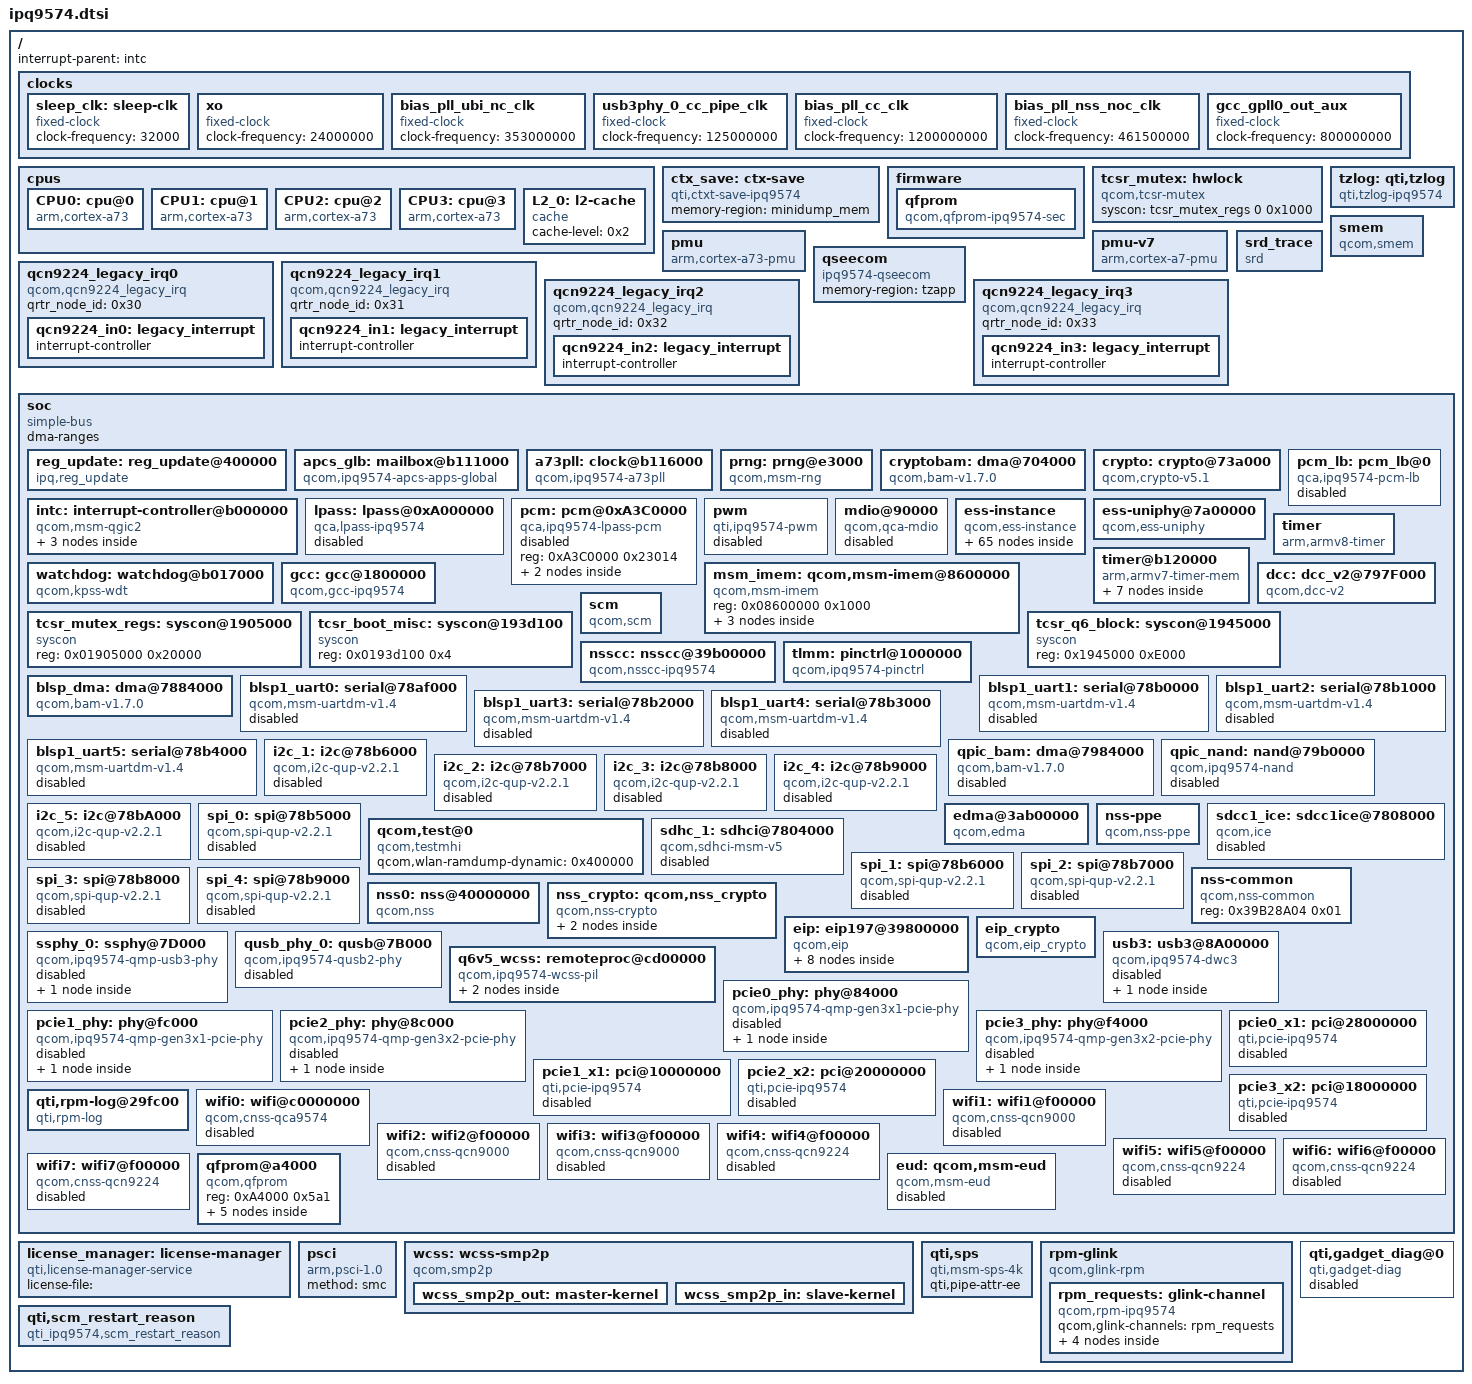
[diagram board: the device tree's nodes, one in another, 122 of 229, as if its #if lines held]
// SPDX-License-Identifier: (GPL-2.0+ OR BSD-3-Clause)
/*
 * IPQ9574 SoC device tree source
 *
 * Copyright (c) 2020-2021 The Linux Foundation. All rights reserved.
 * Copyright (c) 2022-2024, Qualcomm Innovation Center, Inc. All rights reserved.
 */

#include <dt-bindings/interrupt-controller/arm-gic.h>
#include <dt-bindings/clock/qcom,gcc-ipq9574.h>
#include <dt-bindings/reset/qcom,gcc-ipq9574.h>
#include <dt-bindings/clock/qcom,nsscc-ipq9574.h>
#include <dt-bindings/reset/qcom,nsscc-ipq9574.h>
#include <dt-bindings/soc/qcom,dcc_v2.h>
#include <dt-bindings/clock/qcom,apss-ipq.h>
#include <dt-bindings/input/input.h>
#include <dt-bindings/gpio/gpio.h>


/ {
	#address-cells = <2>;
	#size-cells = <2>;
	interrupt-parent = <&intc>;

	clocks {
		sleep_clk: sleep-clk {
			compatible = "fixed-clock";
			clock-frequency = <32000>;
			#clock-cells = <0>;
		};

		xo: xo {
			compatible = "fixed-clock";
			clock-frequency = <24000000>;
			#clock-cells = <0>;
		};

		bias_pll_ubi_nc_clk: bias_pll_ubi_nc_clk {
			compatible = "fixed-clock";
			clock-frequency = <353000000>;
			#clock-cells = <0>;
		};

		usb3phy_0_cc_pipe_clk: usb3phy_0_cc_pipe_clk {
			compatible = "fixed-clock";
			clock-frequency = <125000000>;
			#clock-cells = <0>;
		};

		bias_pll_cc_clk: bias_pll_cc_clk {
			compatible = "fixed-clock";
			clock-frequency = <1200000000>;
			#clock-cells = <0>;
		};

		bias_pll_nss_noc_clk: bias_pll_nss_noc_clk {
			compatible = "fixed-clock";
			clock-frequency = <461500000>;
			#clock-cells = <0>;
		};

		gcc_gpll0_out_aux: gcc_gpll0_out_aux {
			compatible = "fixed-clock";
			clock-frequency = <800000000>;
			#clock-cells = <0>;
		};
	};

	cpus: cpus {
		#address-cells = <1>;
		#size-cells = <0>;

		CPU0: cpu@0 {
			device_type = "cpu";
			compatible = "arm,cortex-a73";
			reg = <0x0>;
			enable-method = "psci";
			next-level-cache = <&L2_0>;
			clocks = <&apcs_glb APCS_ALIAS0_CORE_CLK>;
			clock-names = "cpu";
		};

		CPU1: cpu@1 {
			device_type = "cpu";
			compatible = "arm,cortex-a73";
			enable-method = "psci";
			reg = <0x1>;
			next-level-cache = <&L2_0>;
			clocks = <&apcs_glb APCS_ALIAS0_CORE_CLK>;
			clock-names = "cpu";
		};

		CPU2: cpu@2 {
			device_type = "cpu";
			compatible = "arm,cortex-a73";
			enable-method = "psci";
			reg = <0x2>;
			next-level-cache = <&L2_0>;
			clocks = <&apcs_glb APCS_ALIAS0_CORE_CLK>;
			clock-names = "cpu";
		};

		CPU3: cpu@3 {
			device_type = "cpu";
			compatible = "arm,cortex-a73";
			enable-method = "psci";
			reg = <0x3>;
			next-level-cache = <&L2_0>;
			clocks = <&apcs_glb APCS_ALIAS0_CORE_CLK>;
			clock-names = "cpu";
		};

		L2_0: l2-cache {
			compatible = "cache";
			cache-level = <0x2>;
		};
	};

	ctx_save: ctx-save {
		compatible = "qti,ctxt-save-ipq9574";
		memory-region = <&minidump_mem>;
	};

	firmware {
		qfprom {
			compatible = "qcom,qfprom-ipq9574-sec";
			img-addr = <0x4A100000>;
			img-size = <0x00500000>;
			scm-cmd-id = <0x1F>;
		};
	};

	tcsr_mutex: hwlock {
		compatible = "qcom,tcsr-mutex";
		syscon = <&tcsr_mutex_regs 0 0x1000>;
		#hwlock-cells = <1>;
	};

	pmu {
		compatible = "arm,cortex-a73-pmu";
		interrupts = <GIC_PPI 7 (GIC_CPU_MASK_SIMPLE(4) | IRQ_TYPE_LEVEL_HIGH)>;
	};

	pmu-v7 {
		compatible = "arm,cortex-a7-pmu";
		interrupts = <GIC_PPI 7 (GIC_CPU_MASK_SIMPLE(4) | IRQ_TYPE_LEVEL_HIGH)>;
	};

	tzlog: qti,tzlog {
		compatible = "qti,tzlog-ipq9574";
		interrupts = <GIC_SPI 244 IRQ_TYPE_EDGE_RISING>;
		qti,tz-diag-buf-size = <0x3000>;
		qti,tz-ring-off = <7>;
		qti,tz-log-pos-info-off = <810>;
		qti,hvc-enabled;
		qti,get-smmu-state;
	};

	smem {
		compatible = "qcom,smem";
		memory-region = <&smem_region>;
		hwlocks = <&tcsr_mutex 3>;
	};

	qseecom: qseecom {
		compatible = "ipq9574-qseecom";
		memory-region = <&tzapp>;
		status = "ok";
	};

	qcn9224_legacy_irq0: qcn9224_legacy_irq0 {
		compatible = "qcom,qcn9224_legacy_irq";
		status = "ok";
		qrtr_node_id = <0x30>;
		qcn9224_in0: legacy_interrupt {
			interrupt-controller;
			#interrupt-cells = <2>;
		};
	};

	qcn9224_legacy_irq1: qcn9224_legacy_irq1 {
		compatible = "qcom,qcn9224_legacy_irq";
		status = "ok";
		qrtr_node_id = <0x31>;
		qcn9224_in1: legacy_interrupt {
			interrupt-controller;
			#interrupt-cells = <2>;
		};
	};

	qcn9224_legacy_irq2: qcn9224_legacy_irq2 {
		compatible = "qcom,qcn9224_legacy_irq";
		status = "ok";
		qrtr_node_id = <0x32>;
		qcn9224_in2: legacy_interrupt {
			interrupt-controller;
			#interrupt-cells = <2>;
		};
	};

	qcn9224_legacy_irq3: qcn9224_legacy_irq3 {
		compatible = "qcom,qcn9224_legacy_irq";
		status = "ok";
		qrtr_node_id = <0x33>;
		qcn9224_in3: legacy_interrupt {
			interrupt-controller;
			#interrupt-cells = <2>;
		};
	};

	srd_trace: srd_trace {
		compatible = "srd";
	};

	soc: soc {
		#address-cells = <1>;
		#size-cells = <1>;
		ranges = <0 0 0 0xffffffff>;
		dma-ranges;
		compatible = "simple-bus";

		reg_update: reg_update@400000 {
			compatible = "ipq,reg_update";
			reg = <0x00400000 0x6148>,<0x39D00020 0x10>;
			reg-names = "memnoc","ubicore";
			clocks = <&nsscc NSS_CC_NSS_CSR_CLK>,
				 <&nsscc NSS_CC_NSSNOC_NSS_CSR_CLK>;
			clock-names = "nss-csr-clk", "nss-nssnoc-csr-clk";
			assigned-clocks = <&nsscc NSS_CC_NSS_CSR_CLK>,
					  <&nsscc NSS_CC_NSSNOC_NSS_CSR_CLK>;
			assigned-clock-rates = <100000000>,<100000000>;
			status = "ok";
		};

		apcs_glb: mailbox@b111000 {
			compatible = "qcom,ipq9574-apcs-apps-global";
			reg = <0x0b111000 0x1000>;
			#clock-cells = <1>;
			clocks = <&a73pll>, <&xo>;
			clock-names = "pll", "xo";
			apcs-max-register = <0xFFC>;

			#mbox-cells = <1>;
		};

		a73pll: clock@b116000 {
			compatible = "qcom,ipq9574-a73pll";
			reg = <0x0b116000 0x40>;
			#clock-cells = <0>;
			clocks = <&xo>;
			clock-names = "xo";
		};

		prng: prng@e3000 {
			compatible = "qcom,msm-rng";
			reg = <0xe3000 0x1000>;
			clocks = <&gcc GCC_PRNG_AHB_CLK>;
			clock-names = "km_clk_src";
			qcom,no-qrng-config;
		};

		cryptobam: dma@704000 {
			compatible = "qcom,bam-v1.7.0";
			reg = <0x00704000 0x20000>;
			interrupts = <GIC_SPI 207 IRQ_TYPE_LEVEL_HIGH>;
			#dma-cells = <1>;
			qcom,ee = <1>;
			qcom,controlled-remotely = <1>;
		};

		crypto: crypto@73a000 {
			compatible = "qcom,crypto-v5.1";
			reg = <0x0073a000 0x6000>;
			dmas = <&cryptobam 2>, <&cryptobam 3>;
			dma-names = "rx", "tx";
			qce,no-clock-init;
			qce,cmd_desc_support;
		};

		intc: interrupt-controller@b000000 {
			compatible = "qcom,msm-qgic2";
			interrupt-controller;
			#interrupt-cells = <0x3>;
			reg = <0x0b000000 0x1000>,  /*GICD*/
				<0x0b002000 0x1000>,  /*GICC*/
				<0x0b001000 0x1000>,  /*GICH*/
				<0x0b004000 0x1000>;  /*GICV*/
			interrupts = <GIC_PPI 9 IRQ_TYPE_LEVEL_HIGH>;
			ranges = <0 0x0b00c000 0x3000>;

			v2m0: v2m@0 {
				compatible = "arm,gic-v2m-frame";
				msi-controller;
				reg = <0x0 0xffd>;
			};

			v2m1: v2m@1 {
				compatible = "arm,gic-v2m-frame";
				msi-controller;
				reg = <0x1000 0xffd>;
			};

			v2m2: v2m@2 {
				compatible = "arm,gic-v2m-frame";
				msi-controller;
				reg = <0x2000 0xffd>;
			};
		};

		lpass: lpass@0xA000000{
			compatible = "qca,lpass-ipq9574";
			reg =  <0xA000000 0x3BFFFF>;
			clocks = <&gcc GCC_LPASS_SWAY_CLK>,
			<&gcc GCC_LPASS_CORE_AXIM_CLK>,
			<&gcc GCC_SNOC_LPASS_CFG_CLK>,
			<&gcc GCC_PCNOC_LPASS_CLK>;
			clock-names = "sway", "axim", "snoc_cfg", "pcnoc";
			resets = <&gcc GCC_LPASS_BCR>;
			reset-names = "lpass";
			status = "disabled";
		};

		pcm: pcm@0xA3C0000{
			compatible = "qca,ipq9574-lpass-pcm";
			reg =  <0xA3C0000 0x23014>;
			status = "disabled";

			pcm0: pcm0@0 {
				interrupts = <0 419 IRQ_TYPE_LEVEL_HIGH>;
				interrupt-names = "out0";
				capture_memory = "lpm";
				playback_memory = "lpm";
				voice_loopback = <0>;
				slave = <0>;
				status = "disabled";
			      };

			pcm1: pcm1@1 {
				interrupts = <0 117 IRQ_TYPE_LEVEL_HIGH>;
				interrupt-names = "out1";
				capture_memory = "lpm";
				playback_memory = "lpm";
				voice_loopback = <0>;
				slave = <0>;
				status = "disabled";
			};

		};

		pcm_lb: pcm_lb@0 {
			compatible = "qca,ipq9574-pcm-lb";
			status = "disabled";
		};

		pwm {
			compatible = "qti,ipq9574-pwm";
			reg = <0x1941010 0x20>;
			clocks = <&gcc GCC_ADSS_PWM_CLK>;
			clock-names = "core";
			src-freq = <100000000>;
			pwm-base-index = <0>;
			used-pwm-indices = <1>, <1>, <1>, <1>;
			status = "disabled";
		};

		mdio@90000 {
			#address-cells = <1>;
			#size-cells = <1>;
			compatible = "qcom,qca-mdio", "qcom,ipq40xx-mdio";
			reg = <0x90000 0x64>, <0x9B000 0x800>;
			clocks = <&gcc GCC_MDIO_AHB_CLK>;
			clock-names = "gcc_mdio_ahb_clk";
			status = "disabled";
		};

		ess-instance {
			compatible = "qcom,ess-instance";
			ess-switch@3a000000 {
				compatible = "qcom,ess-switch-ipq95xx";
				switch_access_mode = "local bus";
				reg = <0x3a000000 0x1000000>;
				switch_cpu_bmp = <0x1>;  /* cpu port bitmap */
				switch_inner_bmp = <0x80>; /*inner port bitmap*/
				clocks = <&gcc GCC_CMN_12GPLL_AHB_CLK>,
					<&gcc GCC_CMN_12GPLL_SYS_CLK>,
					<&gcc GCC_UNIPHY0_AHB_CLK>,
					<&gcc GCC_UNIPHY0_SYS_CLK>,
					<&gcc GCC_UNIPHY1_AHB_CLK>,
					<&gcc GCC_UNIPHY1_SYS_CLK>,
					<&gcc GCC_UNIPHY2_AHB_CLK>,
					<&gcc GCC_UNIPHY2_SYS_CLK>,
					<&gcc GCC_NSSNOC_NSSCC_CLK>,
					<&gcc GCC_NSSCC_CLK>,
					<&gcc GCC_NSSNOC_SNOC_1_CLK>,
					<&gcc GCC_NSSNOC_SNOC_CLK>,
					<&nsscc NSS_CC_PORT1_MAC_CLK>,
					<&nsscc NSS_CC_PORT2_MAC_CLK>,
					<&nsscc NSS_CC_PORT3_MAC_CLK>,
					<&nsscc NSS_CC_PORT4_MAC_CLK>,
					<&nsscc NSS_CC_PORT5_MAC_CLK>,
					<&nsscc NSS_CC_PORT6_MAC_CLK>,
					<&nsscc NSS_CC_PPE_SWITCH_CLK>,
					<&nsscc NSS_CC_PPE_SWITCH_CFG_CLK>,
					<&nsscc NSS_CC_NSSNOC_PPE_CLK>,
					<&nsscc NSS_CC_NSSNOC_PPE_CFG_CLK>,
					<&nsscc NSS_CC_PPE_EDMA_CLK>,
					<&nsscc NSS_CC_PPE_EDMA_CFG_CLK>,
					<&nsscc NSS_CC_PPE_SWITCH_IPE_CLK>,
					<&nsscc NSS_CC_PPE_SWITCH_BTQ_CLK>,
					<&nsscc NSS_CC_PORT1_RX_CLK>,
					<&nsscc NSS_CC_PORT1_TX_CLK>,
					<&nsscc NSS_CC_PORT2_RX_CLK>,
					<&nsscc NSS_CC_PORT2_TX_CLK>,
					<&nsscc NSS_CC_PORT3_RX_CLK>,
					<&nsscc NSS_CC_PORT3_TX_CLK>,
					<&nsscc NSS_CC_PORT4_RX_CLK>,
					<&nsscc NSS_CC_PORT4_TX_CLK>,
					<&nsscc NSS_CC_PORT5_RX_CLK>,
					<&nsscc NSS_CC_PORT5_TX_CLK>,
					<&nsscc NSS_CC_PORT6_RX_CLK>,
					<&nsscc NSS_CC_PORT6_TX_CLK>,
					<&nsscc NSS_CC_UNIPHY_PORT1_RX_CLK>,
					<&nsscc NSS_CC_UNIPHY_PORT1_TX_CLK>,
					<&nsscc NSS_CC_UNIPHY_PORT2_RX_CLK>,
					<&nsscc NSS_CC_UNIPHY_PORT2_TX_CLK>,
					<&nsscc NSS_CC_UNIPHY_PORT3_RX_CLK>,
					<&nsscc NSS_CC_UNIPHY_PORT3_TX_CLK>,
					<&nsscc NSS_CC_UNIPHY_PORT4_RX_CLK>,
					<&nsscc NSS_CC_UNIPHY_PORT4_TX_CLK>,
					<&nsscc NSS_CC_UNIPHY_PORT5_RX_CLK>,
					<&nsscc NSS_CC_UNIPHY_PORT5_TX_CLK>,
					<&nsscc NSS_CC_UNIPHY_PORT6_RX_CLK>,
					<&nsscc NSS_CC_UNIPHY_PORT6_TX_CLK>,
					<&nsscc NSS_CC_PORT5_RX_CLK_SRC>,
					<&nsscc NSS_CC_PORT5_TX_CLK_SRC>;
				clock-names = "cmn_ahb_clk",
					"cmn_sys_clk",
					"uniphy0_ahb_clk",
					"uniphy0_sys_clk",
					"uniphy1_ahb_clk",
					"uniphy1_sys_clk",
					"uniphy2_ahb_clk",
					"uniphy2_sys_clk",
					"gcc_nssnoc_nsscc_clk",
					"gcc_nsscc_clk",
					"gcc_nssnoc_snoc_1_clk",
					"gcc_nssnoc_snoc_clk",
					"port1_mac_clk",
					"port2_mac_clk",
					"port3_mac_clk",
					"port4_mac_clk",
					"port5_mac_clk",
					"port6_mac_clk",
					"nss_ppe_clk",
					"nss_ppe_cfg_clk",
					"nssnoc_ppe_clk",
					"nssnoc_ppe_cfg_clk",
					"nss_edma_clk",
					"nss_edma_cfg_clk",
					"nss_ppe_ipe_clk",
					"nss_ppe_btq_clk",
					"nss_port1_rx_clk", "nss_port1_tx_clk",
					"nss_port2_rx_clk", "nss_port2_tx_clk",
					"nss_port3_rx_clk", "nss_port3_tx_clk",
					"nss_port4_rx_clk", "nss_port4_tx_clk",
					"nss_port5_rx_clk", "nss_port5_tx_clk",
					"nss_port6_rx_clk", "nss_port6_tx_clk",
					"uniphy0_port1_rx_clk",
					"uniphy0_port1_tx_clk",
					"uniphy0_port2_rx_clk",
					"uniphy0_port2_tx_clk",
					"uniphy0_port3_rx_clk",
					"uniphy0_port3_tx_clk",
					"uniphy0_port4_rx_clk",
					"uniphy0_port4_tx_clk",
					"uniphy0_port5_rx_clk",
					"uniphy0_port5_tx_clk",
					"uniphy2_port6_rx_clk",
					"uniphy2_port6_tx_clk",
					"nss_port5_rx_clk_src",
					"nss_port5_tx_clk_src";
				resets = <&nsscc PPE_FULL_RESET>,
					<&nsscc UNIPHY0_SOFT_RESET>,
					<&gcc GCC_UNIPHY0_XPCS_RESET>,
					<&nsscc UNIPHY_PORT5_ARES>,
					<&gcc GCC_UNIPHY1_XPCS_RESET>,
					<&nsscc UNIPHY_PORT6_ARES>,
					<&gcc GCC_UNIPHY2_XPCS_RESET>,
					<&nsscc UNIPHY_PORT1_ARES>,
					<&nsscc UNIPHY_PORT2_ARES>,
					<&nsscc UNIPHY_PORT3_ARES>,
					<&nsscc UNIPHY_PORT4_ARES>,
					<&gcc GCC_UNIPHY0_SYS_RESET>,
					<&gcc GCC_UNIPHY1_SYS_RESET>,
					<&gcc GCC_UNIPHY2_SYS_RESET>,
					<&nsscc NSSPORT1_RESET>,
					<&nsscc NSSPORT2_RESET>,
					<&nsscc NSSPORT3_RESET>,
					<&nsscc NSSPORT4_RESET>,
					<&nsscc NSSPORT5_RESET>,
					<&nsscc NSSPORT6_RESET>,
					<&nsscc PORT1_MAC_ARES>,
					<&nsscc PORT2_MAC_ARES>,
					<&nsscc PORT3_MAC_ARES>,
					<&nsscc PORT4_MAC_ARES>,
					<&nsscc PORT5_MAC_ARES>,
					<&nsscc PORT6_MAC_ARES>;
				reset-names = "ppe_rst",
					"uniphy0_soft_rst",
					"uniphy0_xpcs_rst",
					"uniphy1_soft_rst",
					"uniphy1_xpcs_rst",
					"uniphy2_soft_rst",
					"uniphy2_xpcs_rst",
					"uniphy0_port1_dis",
					"uniphy0_port2_dis",
					"uniphy0_port3_dis",
					"uniphy0_port4_dis",
					"uniphy0_sys_rst",
					"uniphy1_sys_rst",
					"uniphy2_sys_rst",
					"nss_port1_rst",
					"nss_port2_rst",
					"nss_port3_rst",
					"nss_port4_rst",
					"nss_port5_rst",
					"nss_port6_rst",
					"nss_port1_mac_rst",
					"nss_port2_mac_rst",
					"nss_port3_mac_rst",
					"nss_port4_mac_rst",
					"nss_port5_mac_rst",
					"nss_port6_mac_rst";
				port_scheduler_resource {
					port@0 {
						port_id = <0>;
						ucast_queue = <0 63>;
						mcast_queue = <256 263>;
						l0sp = <0 0>;
						l0cdrr = <0 7>;
						l0edrr = <0 7>;
						l1cdrr = <0 0>;
						l1edrr = <0 0>;
					};
					port@1 {
						port_id = <1>;
						ucast_queue = <204 211>;
						mcast_queue = <272 275>;
						l0sp = <51 52>;
						l0cdrr = <108 115>;
						l0edrr = <108 115>;
						l1cdrr = <23 24>;
						l1edrr = <23 24>;
					};
					port@2 {
						port_id = <2>;
						ucast_queue = <212 219>;
						mcast_queue = <276 279>;
						l0sp = <53 54>;
						l0cdrr = <116 123>;
						l0edrr = <116 123>;
						l1cdrr = <25 26>;
						l1edrr = <25 26>;
					};
					port@3 {
						port_id = <3>;
						ucast_queue = <220 227>;
						mcast_queue = <280 283>;
						l0sp = <55 56>;
						l0cdrr = <124 131>;
						l0edrr = <124 131>;
						l1cdrr = <27 28>;
						l1edrr = <27 28>;
					};
					port@4 {
						port_id = <4>;
						ucast_queue = <228 235>;
						mcast_queue = <284 287>;
						l0sp = <57 58>;
						l0cdrr = <132 139>;
						l0edrr = <132 139>;
						l1cdrr = <29 30>;
						l1edrr = <29 30>;
					};
					port@5 {
						port_id = <5>;
						ucast_queue = <236 243>;
						mcast_queue = <288 291>;
						l0sp = <59 60>;
						l0cdrr = <140 147>;
						l0edrr = <140 147>;
						l1cdrr = <31 32>;
						l1edrr = <31 32>;
					};
					port@6 {
						port_id = <6>;
						ucast_queue = <244 251>;
						mcast_queue = <292 295>;
						l0sp = <61 62>;
						l0cdrr = <148 155>;
						l0edrr = <148 155>;
						l1cdrr = <33 34>;
						l1edrr = <33 34>;
					};
					port@7 {
						port_id = <7>;
						ucast_queue = <252 255>;
						mcast_queue = <296 299>;
						l0sp = <63 63>;
						l0cdrr = <156 159>;
						l0edrr = <156 159>;
						l1cdrr = <35 35>;
						l1edrr = <35 35>;
					};
					reserved {
						ucast_queue = <64 203>;
						mcast_queue = <264 271>;
						l0sp = <1 50>;
						l0cdrr = <8 107>;
						l0edrr = <8 107>;
						l1cdrr = <1 22>;
						l1edrr = <1 22>;
					};
				};
				port_scheduler_config {
					port@0 {
						port_id = <0>;
						l1scheduler {
							group@0 {
								/* L0 SP */
								sp = <0>;
								/* cpri cdrr epri edrr */
								cfg = <0 0 0 0>;
							};
						};
						l0scheduler {
							group@0 {
								/* unicast queue */
								ucast_queue = <0>;
								ucast_loop_pri = <8>;
								/* multicast queue */
								mcast_queue = <256>;
								/* sp cpri cdrr epri edrr */
								cfg = <0 0 0 0 0>;
							};
							group@1 {
								ucast_queue = <8>;
								ucast_loop_pri = <8>;
								mcast_queue = <257>;
								cfg = <0 0 0 0 0>;
							};
							group@2 {
								ucast_queue = <16>;
								ucast_loop_pri = <8>;
								mcast_queue = <258>;
								cfg = <0 0 0 0 0>;
							};
							group@3 {
								ucast_queue = <24>;
								ucast_loop_pri = <8>;
								mcast_queue = <259>;
								cfg = <0 0 0 0 0>;
							};
							group@4 {
								ucast_queue = <32>;
								ucast_loop_pri = <8>;
								mcast_queue = <260>;
								cfg = <0 0 0 0 0>;
							};
							group@5 {
								ucast_queue = <40>;
								ucast_loop_pri = <8>;
								mcast_queue = <261>;
								cfg = <0 0 0 0 0>;
							};
							group@6 {
								ucast_queue = <48>;
								ucast_loop_pri = <8>;
								mcast_queue = <262>;
								cfg = <0 0 0 0 0>;
							};
							group@7 {
								ucast_queue = <56>;
								ucast_loop_pri = <8>;
								mcast_queue = <263>;
								cfg = <0 0 0 0 0>;
							};
						};
					};
					port@1 {
						port_id = <1>;
						l1scheduler {
							group@0 {
								sp = <51>;
								cfg = <0 23 0 23>;
							};
							group@1 {
								sp = <52>;
								cfg = <1 24 1 24>;
							};
						};
						l0scheduler {
							group@0 {
								ucast_queue = <204>;
								ucast_loop_pri = <8>;
								/* max priority per SP */
								ucast_max_pri = <4>;
								mcast_queue = <272>;
								mcast_loop_pri = <4>;
								cfg = <51 0 108 0 108>;
							};
						};
					};
					port@2 {
						port_id = <2>;
						l1scheduler {
							group@0 {
								sp = <53>;
								cfg = <0 25 0 25>;
							};
							group@1 {
								sp = <54>;
								cfg = <1 26 1 26>;
							};
						};
						l0scheduler {
							group@0 {
								ucast_queue = <212>;
								ucast_loop_pri = <8>;
								ucast_max_pri = <4>;
								mcast_queue = <276>;
								mcast_loop_pri = <4>;
								cfg = <53 0 116 0 116>;
							};
						};
					};
					port@3 {
						port_id = <3>;
						l1scheduler {
							group@0 {
								sp = <55>;
								cfg = <0 27 0 27>;
							};
							group@1 {
								sp = <56>;
								cfg = <1 28 1 28>;
							};
						};
						l0scheduler {
							group@0 {
								ucast_queue = <220>;
								ucast_loop_pri = <8>;
								ucast_max_pri = <4>;
								mcast_queue = <280>;
								mcast_loop_pri = <4>;
								cfg = <55 0 124 0 124>;
							};
						};
					};
					port@4 {
						port_id = <4>;
						l1scheduler {
							group@0 {
								sp = <57>;
								cfg = <0 29 0 29>;
							};
							group@1 {
								sp = <58>;
								cfg = <1 30 1 30>;
							};
						};
						l0scheduler {
							group@0 {
								ucast_queue = <228>;
								ucast_loop_pri = <8>;
								ucast_max_pri = <4>;
								mcast_queue = <284>;
								mcast_loop_pri = <4>;
								cfg = <57 0 132 0 132>;
							};
						};
					};
					port@5 {
						port_id = <5>;
						l1scheduler {
							group@0 {
								sp = <59>;
								cfg = <0 31 0 31>;
							};
							group@1 {
								sp = <60>;
								cfg = <1 32 1 32>;
							};
						};
						l0scheduler {
							group@0 {
								ucast_queue = <236>;
								ucast_loop_pri = <8>;
								ucast_max_pri = <4>;
								mcast_queue = <288>;
								mcast_loop_pri = <4>;
								cfg = <59 0 140 0 140>;
							};
						};
					};
					port@6 {
						port_id = <6>;
						l1scheduler {
							group@0 {
								sp = <61>;
								cfg = <0 33 0 33>;
							};
							group@1 {
								sp = <62>;
								cfg = <1 34 1 34>;
							};
						};
						l0scheduler {
							group@0 {
								ucast_queue = <244>;
								ucast_loop_pri = <8>;
								ucast_max_pri = <4>;
								mcast_queue = <292>;
								mcast_loop_pri = <4>;
								cfg = <61 0 148 0 148>;
							};
						};
					};
					port@7 {
						port_id = <7>;
						l1scheduler {
							group@0 {
								sp = <63>;
								cfg = <0 35 0 35>;
							};
						};
						l0scheduler {
							group@0 {
								ucast_queue = <252>;
								ucast_loop_pri = <4>;
								ucast_max_pri = <4>;
								mcast_queue = <296>;
								mcast_loop_pri = <4>;
								cfg = <63 0 156 0 156>;
							};
						};
					};
				};
			};
		};

		ess-uniphy@7a00000 {
			compatible = "qcom,ess-uniphy";
			reg = <0x7a00000 0x30000>;
			uniphy_access_mode = "local bus";
		};

		timer {
			compatible = "arm,armv8-timer";
			interrupts = <GIC_PPI 2 (GIC_CPU_MASK_SIMPLE(4) | IRQ_TYPE_LEVEL_LOW)>,
				<GIC_PPI 3 (GIC_CPU_MASK_SIMPLE(4) | IRQ_TYPE_LEVEL_LOW)>,
				<GIC_PPI 4 (GIC_CPU_MASK_SIMPLE(4) | IRQ_TYPE_LEVEL_LOW)>,
				<GIC_PPI 1 (GIC_CPU_MASK_SIMPLE(4) | IRQ_TYPE_LEVEL_LOW)>;
			clock-frequency = <24000000>;
		};

		watchdog: watchdog@b017000 {
			compatible = "qcom,kpss-wdt";
			reg = <0xb017000 0x1000>;
			interrupts = <GIC_SPI 3 IRQ_TYPE_EDGE_RISING>;
			clocks = <&sleep_clk>;
		};

		timer@b120000 {
			#address-cells = <1>;
			#size-cells = <1>;
			ranges;
			compatible = "arm,armv7-timer-mem";
			reg = <0xb120000 0x1000>;
			clock-frequency = <24000000>;

			frame@b120000 {
				frame-number = <0>;
				interrupts = <GIC_SPI 8 IRQ_TYPE_LEVEL_HIGH>,
					     <GIC_SPI 7 IRQ_TYPE_LEVEL_HIGH>;
				reg = <0xb121000 0x1000>,
				      <0xb122000 0x1000>;
			};

			frame@b123000 {
				frame-number = <1>;
				interrupts = <GIC_SPI 9 IRQ_TYPE_LEVEL_HIGH>;
				reg = <0xb123000 0x1000>;
				status = "disabled";
			};

			frame@b124000 {
				frame-number = <2>;
				interrupts = <GIC_SPI 10 IRQ_TYPE_LEVEL_HIGH>;
				reg = <0xb124000 0x1000>;
				status = "disabled";
			};

			frame@b125000 {
				frame-number = <3>;
				interrupts = <GIC_SPI 11 IRQ_TYPE_LEVEL_HIGH>;
				reg = <0xb125000 0x1000>;
				status = "disabled";
			};

			frame@b126000 {
				frame-number = <4>;
				interrupts = <GIC_SPI 12 IRQ_TYPE_LEVEL_HIGH>;
				reg = <0xb126000 0x1000>;
				status = "disabled";
			};

			frame@b127000 {
				frame-number = <5>;
				interrupts = <GIC_SPI 13 IRQ_TYPE_LEVEL_HIGH>;
				reg = <0xb127000 0x1000>;
				status = "disabled";
			};

			frame@b128000 {
				frame-number = <6>;
				interrupts = <GIC_SPI 14 IRQ_TYPE_LEVEL_HIGH>;
				reg = <0xb128000 0x1000>;
				status = "disabled";
			};
		};

		gcc: gcc@1800000 {
			compatible = "qcom,gcc-ipq9574";
			reg = <0x1800000 0x80000>;
			clocks = <&xo>, <&sleep_clk>;
			clock-names = "xo", "sleep_clk";
			#clock-cells = <0x1>;
			#reset-cells = <0x1>;
		};

		msm_imem: qcom,msm-imem@8600000 {
			compatible = "qcom,msm-imem";
			reg = <0x08600000 0x1000>;
			ranges = <0x0 0x08600000 0x1000>;
			#address-cells = <1>;
			#size-cells = <1>;

			mem_dump_table@10 {
				compatible = "qcom,msm-imem-mem_dump_table";
				reg = <0x10 8>;
			};

			tz-log-buf-addr@720 {
				compatible = "qcom,msm-imem-tz-log-buf-addr";
				reg = <0x720 4>;
			};

			restart-reason-buf-addr@7a4 {
				compatible = "qcom,msm-imem-restart-reason-buf-addr";
				reg = <0x7a4 4>;
			};
		};

		dcc: dcc_v2@797F000 {
			compatible = "qcom,dcc-v2";
			status = "ok";
			reg = <0x797F000 0x1000>,
				<0x7906000 0x1000>;
			reg-names = "dcc-base", "dcc-ram-base";

			dcc-ram-offset = <0x6000>;
		};

		tcsr_mutex_regs: syscon@1905000 {
			compatible = "syscon";
			reg = <0x01905000 0x20000>;
		};

		tcsr_boot_misc: syscon@193d100 {
			compatible = "syscon";
			reg = <0x0193d100 0x4>;
		};

		tcsr_q6_block: syscon@1945000 {
			compatible = "syscon";
			reg = <0x1945000 0xE000>;
		};

		scm {
			compatible = "qcom,scm";
			hvc-log-cmd-id = <0xA>;
			smmu-state-cmd-id = <0x20>;
			qcom,dload-mode = <&tcsr_boot_misc 0>;
		};

		nsscc: nsscc@39b00000 {
			compatible = "qcom,nsscc-ipq9574";
			reg = <0x39b00000 0x80000>;
			clocks = <&bias_pll_cc_clk>,
				<&bias_pll_nss_noc_clk>,
				<&bias_pll_ubi_nc_clk>,
				<&gcc_gpll0_out_aux>,
				<&xo>;
			clock-names = "bias_pll_cc_clk",
				"bias_pll_nss_noc_clk",
				"bias_pll_ubi_nc_clk",
				"gcc_gpll0_out_aux",
				"xo";
			#clock-cells = <0x1>;
			#reset-cells = <0x1>;
		};

		tlmm: pinctrl@1000000 {
			compatible = "qcom,ipq9574-pinctrl";
			reg = <0x01000000 0x300000>;
			interrupts = <GIC_SPI 208 IRQ_TYPE_LEVEL_HIGH>;
			gpio-controller;
			#gpio-cells = <2>;
			gpio-ranges = <&tlmm 0 0 65>;
			gpio-reserved-ranges = <59 1>;
			interrupt-controller;
			#interrupt-cells = <2>;
		};

		blsp_dma: dma@7884000 {
			compatible = "qcom,bam-v1.7.0";
			reg = <0x07884000 0x2b000>;
			interrupts = <GIC_SPI 238 IRQ_TYPE_LEVEL_HIGH>;
			clocks = <&gcc GCC_BLSP1_AHB_CLK>;
			clock-names = "bam_clk";
			#dma-cells = <1>;
			qcom,ee = <0>;
		};

		blsp1_uart0: serial@78af000 {
			compatible = "qcom,msm-uartdm-v1.4", "qcom,msm-uartdm";
			reg = <0x078af000 0x200>;
			interrupts = <GIC_SPI 107 IRQ_TYPE_LEVEL_HIGH>;
			clocks = <&gcc GCC_BLSP1_UART1_APPS_CLK>,
				 <&gcc GCC_BLSP1_AHB_CLK>;
			clock-names = "core", "iface";
			status = "disabled";
		};

		blsp1_uart1: serial@78b0000 {
			compatible = "qcom,msm-uartdm-v1.4", "qcom,msm-uartdm";
			reg = <0x078b0000 0x200>;
			interrupts = <GIC_SPI 108 IRQ_TYPE_LEVEL_HIGH>;
			clocks = <&gcc GCC_BLSP1_UART2_APPS_CLK>,
				 <&gcc GCC_BLSP1_AHB_CLK>;
			clock-names = "core", "iface";
			status = "disabled";
		};

		blsp1_uart2: serial@78b1000 {
			compatible = "qcom,msm-uartdm-v1.4", "qcom,msm-uartdm";
			reg = <0x078b1000 0x200>;
			interrupts = <GIC_SPI 306 IRQ_TYPE_LEVEL_HIGH>;
			clocks = <&gcc GCC_BLSP1_UART3_APPS_CLK>,
				 <&gcc GCC_BLSP1_AHB_CLK>;
			clock-names = "core", "iface";
			status = "disabled";
			tx-watermark = <0>;
		};

		blsp1_uart3: serial@78b2000 {
			compatible = "qcom,msm-uartdm-v1.4", "qcom,msm-uartdm";
			reg = <0x078b2000 0x200>;
			interrupts = <GIC_SPI 307 IRQ_TYPE_LEVEL_HIGH>;
			clocks = <&gcc GCC_BLSP1_UART4_APPS_CLK>,
				 <&gcc GCC_BLSP1_AHB_CLK>;
			clock-names = "core", "iface";
			status = "disabled";
		};

		blsp1_uart4: serial@78b3000 {
			compatible = "qcom,msm-uartdm-v1.4", "qcom,msm-uartdm";
			reg = <0x078b3000 0x200>;
			interrupts = <GIC_SPI 308 IRQ_TYPE_LEVEL_HIGH>;
			clocks = <&gcc GCC_BLSP1_UART5_APPS_CLK>,
				 <&gcc GCC_BLSP1_AHB_CLK>;
			clock-names = "core", "iface";
			dmas = <&blsp_dma 8>, <&blsp_dma 9>;
			dma-names = "tx", "rx";
			status = "disabled";
		};

		blsp1_uart5: serial@78b4000 {
			compatible = "qcom,msm-uartdm-v1.4", "qcom,msm-uartdm";
			reg = <0x078b4000 0x200>;
			interrupts = <GIC_SPI 309 IRQ_TYPE_LEVEL_HIGH>;
			clocks = <&gcc GCC_BLSP1_UART6_APPS_CLK>,
				 <&gcc GCC_BLSP1_AHB_CLK>;
			clock-names = "core", "iface";
			status = "disabled";
		};

		qpic_bam: dma@7984000 {
			compatible = "qcom,bam-v1.7.0";
			reg = <0x7984000 0x1c000>;
			interrupts = <GIC_SPI 146 IRQ_TYPE_LEVEL_HIGH>;
			clocks = <&gcc GCC_QPIC_AHB_CLK>;
			clock-names = "bam_clk";
			#dma-cells = <1>;
			qcom,ee = <0>;
			status = "disabled";
		};

		qpic_nand: nand@79b0000 {
			compatible = "qcom,ipq9574-nand";
			reg = <0x79b0000 0x10000>;
			#address-cells = <1>;
			#size-cells = <0>;
			clocks = <&gcc GCC_QPIC_CLK>,
			<&gcc GCC_QPIC_AHB_CLK>,
			<&gcc GCC_QPIC_IO_MACRO_CLK>;
			clock-names = "core", "aon", "io_macro";

			dmas = <&qpic_bam 0>,
				<&qpic_bam 1>,
				<&qpic_bam 2>,
				<&qpic_bam 3>;
			dma-names = "tx", "rx", "cmd", "sts";
			status = "disabled";
		};

		i2c_1: i2c@78b6000 {
			compatible = "qcom,i2c-qup-v2.2.1";
			#address-cells = <1>;
			#size-cells = <0>;
			reg = <0x78b6000 0x600>;
			interrupts = <GIC_SPI 96 IRQ_TYPE_LEVEL_HIGH>;
			clocks = <&gcc GCC_BLSP1_AHB_CLK>,
				<&gcc GCC_BLSP1_QUP2_I2C_APPS_CLK>;
			clock-names = "iface", "core";
			clock-frequency  = <400000>;
			dmas = <&blsp_dma 15>, <&blsp_dma 14>;
			dma-names = "rx", "tx";
			status = "disabled";
		};

		i2c_2: i2c@78b7000 {
			compatible = "qcom,i2c-qup-v2.2.1";
			#address-cells = <1>;
			#size-cells = <0>;
			reg = <0x78b7000 0x600>;
			interrupts = <GIC_SPI 97 IRQ_TYPE_LEVEL_HIGH>;
			clocks = <&gcc GCC_BLSP1_AHB_CLK>,
				<&gcc GCC_BLSP1_QUP3_I2C_APPS_CLK>;
			clock-names = "iface", "core";
			clock-frequency  = <400000>;
			dmas = <&blsp_dma 17>, <&blsp_dma 16>;
			dma-names = "rx", "tx";
			status = "disabled";
		};

		i2c_3: i2c@78b8000 {
			compatible = "qcom,i2c-qup-v2.2.1";
			#address-cells = <1>;
			#size-cells = <0>;
			reg = <0x78b8000 0x600>;
			interrupts = <GIC_SPI 98 IRQ_TYPE_LEVEL_HIGH>;
			clocks = <&gcc GCC_BLSP1_AHB_CLK>,
				<&gcc GCC_BLSP1_QUP4_I2C_APPS_CLK>;
			clock-names = "iface", "core";
			clock-frequency  = <400000>;
			dmas = <&blsp_dma 19>, <&blsp_dma 18>;
			dma-names = "rx", "tx";
			status = "disabled";
		};

		i2c_4: i2c@78b9000 {
			compatible = "qcom,i2c-qup-v2.2.1";
			#address-cells = <1>;
			#size-cells = <0>;
			reg = <0x78b9000 0x600>;
			interrupts = <GIC_SPI 299 IRQ_TYPE_LEVEL_HIGH>;
			clocks = <&gcc GCC_BLSP1_AHB_CLK>,
				<&gcc GCC_BLSP1_QUP5_I2C_APPS_CLK>;
			clock-names = "iface", "core";
			clock-frequency  = <400000>;
			dmas = <&blsp_dma 21>, <&blsp_dma 20>;
			dma-names = "rx", "tx";
			status = "disabled";
		};

		i2c_5: i2c@78bA000 {
			compatible = "qcom,i2c-qup-v2.2.1";
			#address-cells = <1>;
			#size-cells = <0>;
			reg = <0x78bA000 0x600>;
			interrupts = <GIC_SPI 300 IRQ_TYPE_LEVEL_HIGH>;
			clocks = <&gcc GCC_BLSP1_AHB_CLK>,
				<&gcc GCC_BLSP1_QUP6_I2C_APPS_CLK>;
			clock-names = "iface", "core";
			clock-frequency  = <400000>;
			dmas = <&blsp_dma 23>, <&blsp_dma 22>;
			dma-names = "rx", "tx";
			status = "disabled";
		};

		spi_0: spi@78b5000 {
			compatible = "qcom,spi-qup-v2.2.1";
			#address-cells = <1>;
			#size-cells = <0>;
			reg = <0x78b5000 0x600>;
			interrupts = <GIC_SPI 95 IRQ_TYPE_LEVEL_HIGH>;
			spi-max-frequency = <50000000>;
			clocks = <&gcc GCC_BLSP1_QUP1_SPI_APPS_CLK>,
				<&gcc GCC_BLSP1_AHB_CLK>;
			clock-names = "core", "iface";
			dmas = <&blsp_dma 12>, <&blsp_dma 13>;
			dma-names = "tx", "rx";
			spi-transfer-timeout = <200>;
			status = "disabled";
		};

		edma@3ab00000 {
			compatible = "qcom,edma";
			reg = <0x3ab00000 0xef800>;
			reg-names = "edma-reg-base";
			resets = <&nsscc EDMA_HW_RESET>;
			reset-names = "edma_rst";
			clocks = <&nsscc NSS_CC_NSS_CSR_CLK>,
				 <&nsscc NSS_CC_NSSNOC_NSS_CSR_CLK>,
				 <&nsscc NSS_CC_IMEM_QSB_CLK>,
				 <&nsscc NSS_CC_NSSNOC_IMEM_QSB_CLK>,
				 <&nsscc NSS_CC_IMEM_AHB_CLK>,
				 <&nsscc NSS_CC_NSSNOC_IMEM_AHB_CLK>,
				 <&nsscc NSS_CC_PPE_EDMA_CLK>,
				 <&gcc GCC_MEM_NOC_NSSNOC_CLK>,
				 <&gcc GCC_NSS_TBU_CLK>,
				 <&gcc GCC_NSS_TS_CLK>,
				 <&gcc GCC_NSSCC_CLK>,
				 <&gcc GCC_NSSCFG_CLK>,
				 <&gcc GCC_NSSNOC_ATB_CLK>,
				 <&gcc GCC_NSSNOC_MEM_NOC_1_CLK>,
				 <&gcc GCC_NSSNOC_MEMNOC_CLK>,
				 <&gcc GCC_NSSNOC_NSSCC_CLK>,
				 <&gcc GCC_NSSNOC_PCNOC_1_CLK>,
				 <&gcc GCC_NSSNOC_QOSGEN_REF_CLK>,
				 <&gcc GCC_NSSNOC_SNOC_1_CLK>,
				 <&gcc GCC_NSSNOC_SNOC_CLK>,
				 <&gcc GCC_NSSNOC_TIMEOUT_REF_CLK>,
				 <&gcc GCC_NSSNOC_XO_DCD_CLK>;
			clock-names = "nss-csr-clk", "nss-nssnoc-csr-clk",
				      "nss-imem-qsb-clk", "nss-nssnoc-imem-qsb-clk",
				      "nss-imem-ahb-clk", "nss-nssnoc-imem-ahb-clk", "nss-edma-clk",
				      "nss-mem-noc-nssnoc-clk", "nss-tbu-clk", "nss-ts-clk",
				      "nss-nsscc-clk", "nss-nsscfg-clk", "nss-nsscnoc-atb-clk",
				      "nss-nssnoc-mem-noc-1-clk", "nss-nssnoc-memnoc-clk", "nss-nssnoc-nsscc-clk",
				      "nss-nssnoc-pcnoc-1-clk", "nss-nssnoc-qosgen-ref-clk", "nss-nssnoc-snoc-1-clk",
				      "nss-nssnoc-snoc-clk", "nss-nssnoc-timeout-ref-clk", "nss-nssnoc-xo-dcd-clk";
		};

		nss-ppe {
			compatible = "qcom,nss-ppe";
		};

		qcom,test@0 {
			compatible = "qcom,testmhi";
			qcom,wlan-ramdump-dynamic = <0x400000>;
			status = "ok";
		};

		sdcc1_ice: sdcc1ice@7808000 {
			compatible = "qcom,ice";
			reg = <0x7808000 0x2000>;
			interrupts = <GIC_SPI 313 IRQ_TYPE_LEVEL_HIGH>;
			qcom,msm-bus,vectors-KBps =
				<78 512 0 0>,    /* No vote */
				<78 512 1000 0>; /* Max. bandwidth */
			qcom,bus-vector-names = "MIN", "MAX";
			qcom,instance-type = "sdcc";
			status = "disabled";
		};

		sdhc_1: sdhci@7804000 {
			compatible = "qcom,sdhci-msm-v5";
			reg = <0x7804000 0x1000>, <0x7805000 0x1000>;
			reg-names = "hc_mem", "cmdq_mem";

			interrupts = <GIC_SPI 123 IRQ_TYPE_LEVEL_HIGH>,
					<GIC_SPI 138 IRQ_TYPE_LEVEL_HIGH>;
			interrupt-names = "hc_irq", "pwr_irq";

			sdhc-msm-crypto = <&sdcc1_ice>;
			clocks = <&xo>,
				<&gcc GCC_SDCC1_AHB_CLK>,
				<&gcc GCC_SDCC1_APPS_CLK>,
				<&gcc GCC_SDCC1_ICE_CORE_CLK>;
			clock-names = "xo", "iface", "core", "ice_core_clk";
			qcom,ice-clk-rates = <150000000 300000000>;
			mmc-ddr-1_8v;
			mmc-hs200-1_8v;
			mmc-hs400-1_8v;
			mmc-hs400-enhanced-strobe;
			max-frequency = <384000000>;
			bus-width = <8>;
			non-removable;
			status = "disabled";
		};

		spi_1: spi@78b6000 {
			compatible = "qcom,spi-qup-v2.2.1";
			#address-cells = <1>;
			#size-cells = <0>;
			reg = <0x78b6000 0x600>;
			interrupts = <GIC_SPI 96 IRQ_TYPE_LEVEL_HIGH>;
			spi-max-frequency = <50000000>;
			clocks = <&gcc GCC_BLSP1_QUP2_SPI_APPS_CLK>,
				<&gcc GCC_BLSP1_AHB_CLK>;
			clock-names = "core", "iface";
			dmas = <&blsp_dma 14>, <&blsp_dma 15>;
			dma-names = "tx", "rx";
			status = "disabled";
		};

		spi_2: spi@78b7000 {
			compatible = "qcom,spi-qup-v2.2.1";
			#address-cells = <1>;
			#size-cells = <0>;
			reg = <0x78b7000 0x600>;
			interrupts = <GIC_SPI 97 IRQ_TYPE_LEVEL_HIGH>;
			spi-max-frequency = <50000000>;
			clocks = <&gcc GCC_BLSP1_QUP3_SPI_APPS_CLK>,
				<&gcc GCC_BLSP1_AHB_CLK>;
			clock-names = "core", "iface";
			dmas = <&blsp_dma 16>, <&blsp_dma 17>;
			dma-names = "tx", "rx";
			status = "disabled";
		};

		spi_3: spi@78b8000 {
			compatible = "qcom,spi-qup-v2.2.1";
			#address-cells = <1>;
			#size-cells = <0>;
			reg = <0x78b8000 0x600>;
			interrupts = <GIC_SPI 98 IRQ_TYPE_LEVEL_HIGH>;
			spi-max-frequency = <50000000>;
			clocks = <&gcc GCC_BLSP1_QUP4_SPI_APPS_CLK>,
				<&gcc GCC_BLSP1_AHB_CLK>;
			clock-names = "core", "iface";
			dmas = <&blsp_dma 18>, <&blsp_dma 19>;
			dma-names = "tx", "rx";
			status = "disabled";
		};

		spi_4: spi@78b9000 {
			compatible = "qcom,spi-qup-v2.2.1";
			#address-cells = <1>;
			#size-cells = <0>;
			reg = <0x78b9000 0x600>;
			interrupts = <GIC_SPI 299 IRQ_TYPE_LEVEL_HIGH>;
			spi-max-frequency = <50000000>;
			clocks = <&gcc GCC_BLSP1_QUP5_SPI_APPS_CLK>,
				<&gcc GCC_BLSP1_AHB_CLK>;
			clock-names = "core", "iface";
			dmas = <&blsp_dma 20>, <&blsp_dma 21>;
			dma-names = "tx", "rx";
			status = "disabled";
		};

		nss-common {
			compatible = "qcom,nss-common";
			reg = <0x39B28A04 0x01>;
			reg-names = "nss-misc-reset";
		};

		nss0: nss@40000000 {
			compatible = "qcom,nss";
			interrupts = <0 431 0x1>, <0 430 0x1>, <0 429 0x1>,
				     <0 428 0x1>, <0 427 0x1>, <0 426 0x1>,
				     <0 425 0x1>, <0 424 0x1>, <0 423 0x1>,
				     <0 422 0x1>;
			reg = <0x38F00000 0x100>, <0x38200000 0xC000>,
			      <0xB11A000 0x1000>;
			reg-names = "nphys", "vphys", "qgic-phys";
			clocks = <&nsscc NSS_CC_NSS_CSR_CLK>,
				 <&nsscc NSS_CC_NSSNOC_NSS_CSR_CLK>,
				 <&nsscc NSS_CC_HAQ_AHB_CLK>,
				 <&nsscc NSS_CC_HAQ_AXI_CLK>,
				 <&nsscc NSS_CC_NSSNOC_HAQ_AHB_CLK>,
				 <&nsscc NSS_CC_NSSNOC_HAQ_AXI_CLK>,
				 <&nsscc NSS_CC_CE_APB_CLK>,
				 <&nsscc NSS_CC_CE_AXI_CLK>,
				 <&nsscc NSS_CC_NSSNOC_CE_APB_CLK>,
				 <&nsscc NSS_CC_NSSNOC_CE_AXI_CLK>,
				 <&nsscc NSS_CC_CLC_AXI_CLK>,
				 <&nsscc NSS_CC_NSSNOC_CLC_AXI_CLK>,
				 <&nsscc NSS_CC_IMEM_QSB_CLK>,
				 <&nsscc NSS_CC_NSSNOC_IMEM_QSB_CLK>,
				 <&nsscc NSS_CC_IMEM_AHB_CLK>,
				 <&nsscc NSS_CC_NSSNOC_IMEM_AHB_CLK>,
				 <&nsscc NSS_CC_NSSNOC_UBI32_AHB0_CLK>,
				 <&nsscc NSS_CC_NSSNOC_UBI32_AXI0_CLK>,
				 <&nsscc NSS_CC_NSSNOC_UBI32_INT0_AHB_CLK>,
				 <&nsscc NSS_CC_NSSNOC_UBI32_NC_AXI0_1_CLK>,
				 <&nsscc NSS_CC_NSSNOC_UBI32_NC_AXI0_CLK>,
				 <&nsscc NSS_CC_UBI32_CORE0_CLK>,
				 <&nsscc NSS_CC_UBI32_AHB0_CLK>,
				 <&nsscc NSS_CC_UBI32_AXI0_CLK>,
				 <&nsscc NSS_CC_UBI32_INTR0_AHB_CLK>,
				 <&nsscc NSS_CC_UBI32_NC_AXI0_CLK>,
				 <&nsscc NSS_CC_UBI32_UTCM0_CLK>,
				 <&gcc GCC_MEM_NOC_NSSNOC_CLK>,
				 <&gcc GCC_NSS_TBU_CLK>,
				 <&gcc GCC_NSS_TS_CLK>,
				 <&gcc GCC_NSSCC_CLK>,
				 <&gcc GCC_NSSCFG_CLK>,
				 <&gcc GCC_NSSNOC_ATB_CLK>,
				 <&gcc GCC_NSSNOC_MEM_NOC_1_CLK>,
				 <&gcc GCC_NSSNOC_MEMNOC_CLK>,
				 <&gcc GCC_NSSNOC_NSSCC_CLK>,
				 <&gcc GCC_NSSNOC_PCNOC_1_CLK>,
				 <&gcc GCC_NSSNOC_QOSGEN_REF_CLK>,
				 <&gcc GCC_NSSNOC_SNOC_1_CLK>,
				 <&gcc GCC_NSSNOC_SNOC_CLK>,
				 <&gcc GCC_NSSNOC_TIMEOUT_REF_CLK>,
				 <&gcc GCC_NSSNOC_XO_DCD_CLK>;
			clock-names = "nss-csr-clk", "nss-nssnoc-csr-clk",
				      "nss-haq-ahb-clk", "nss-haq-axi-clk",
				      "nss-nssnoc-haq-ahb-clk", "nss-nssnoc-haq-axi-clk",
				      "nss-ce-ahb-clk", "nss-ce-axi-clk",
				      "nss-nssnoc-ce-ahb-clk", "nss-nssnoc-ce-axi-clk",
				      "nss-clc-axi-clk", "nss-nssnoc-clc-axi-clk",
				      "nss-imem-qsb-clk", "nss-nssnoc-imem-qsb-clk",
				      "nss-imem-ahb-clk", "nss-nssnoc-imem-ahb-clk",
				      "nss-nssnoc-ahb0-clk", "nss-nssnoc-axi0-clk",
				      "nss-nssnoc-int0-ahb-clk", "nss-nssnoc-nc-axi0-1-clk",
				      "nss-nssnoc-nc-axi0-clk",
				      "nss-core-clk", "nss-ahb-clk", "nss-axi-clk",
				      "nss-intr-ahb-clk", "nss-nc-axi-clk", "nss-utcm-clk",
				      "nss-mem-noc-nssnoc-clk", "nss-tbu-clk", "nss-ts-clk",
				      "nss-nsscc-clk", "nss-nsscfg-clk", "nss-nsscnoc-atb-clk",
				      "nss-nssnoc-mem-noc-1-clk", "nss-nssnoc-memnoc-clk", "nss-nssnoc-nsscc-clk",
				      "nss-nssnoc-pcnoc-1-clk", "nss-nssnoc-qosgen-ref-clk", "nss-nssnoc-snoc-1-clk",
				      "nss-nssnoc-snoc-clk", "nss-nssnoc-timeout-ref-clk", "nss-nssnoc-xo-dcd-clk";
			qcom,id = <0>;
			qcom,num-queue = <4>;
			qcom,num-irq = <10>;
			qcom,num-pri = <4>;
			qcom,load-addr = <0x40000000>;
			qcom,low-frequency = <748800000>;
			qcom,mid-frequency = <1497600000>;
			qcom,max-frequency = <1689600000>;
			qcom,edma-lite-enabled;
			qcom,capwap-enabled;
			qcom,trustsec-enabled;
			qcom,dtls-enabled;
			qcom,crypto-enabled;
			npu-supply = <&npu_vreg>;
			mx-supply = <&ipq9574_s4>;
		};

		nss_crypto: qcom,nss_crypto {
			compatible = "qcom,nss-crypto";
			#address-cells = <1>;
			#size-cells = <1>;
			qcom,max-contexts = <64>;
			qcom,max-context-size = <32>;
			status = "ok";
			ranges;

			eip197_node {
				compatible = "qcom,eip197";
				reg-names = "crypto_pbase";
				reg = <0x39800000 0x7ffff>;
				clocks = <&nsscc NSS_CC_CRYPTO_CLK>,
					<&nsscc NSS_CC_NSSNOC_CRYPTO_CLK>,
					<&nsscc NSS_CC_CRYPTO_PPE_CLK>;
				clock-names = "crypto_clk", "crypto_nocclk",
						"crypto_ppeclk";
				clock-frequency = /bits/ 64 <600000000 600000000 300000000>;
				qcom,dma-mask = <0xff>;
				qcom,transform-enabled;
				qcom,aes128-cbc;
				qcom,aes192-cbc;
				qcom,aes256-cbc;
				qcom,aes128-ctr;
				qcom,aes192-ctr;
				qcom,aes256-ctr;
				qcom,aes128-ecb;
				qcom,aes192-ecb;
				qcom,aes256-ecb;
				qcom,3des-cbc;
				qcom,md5-hash;
				qcom,sha160-hash;
				qcom,sha224-hash;
				qcom,sha384-hash;
				qcom,sha512-hash;
				qcom,sha256-hash;
				qcom,md5-hmac;
				qcom,sha160-hmac;
				qcom,sha224-hmac;
				qcom,sha256-hmac;
				qcom,sha384-hmac;
				qcom,sha512-hmac;
				qcom,aes128-gcm-gmac;
				qcom,aes192-gcm-gmac;
				qcom,aes256-gcm-gmac;
				qcom,aes128-cbc-md5-hmac;
				qcom,aes128-cbc-sha160-hmac;
				qcom,aes192-cbc-md5-hmac;
				qcom,aes192-cbc-sha160-hmac;
				qcom,aes256-cbc-md5-hmac;
				qcom,aes256-cbc-sha160-hmac;
				qcom,aes128-ctr-sha160-hmac;
				qcom,aes192-ctr-sha160-hmac;
				qcom,aes256-ctr-sha160-hmac;
				qcom,aes128-ctr-md5-hmac;
				qcom,aes192-ctr-md5-hmac;
				qcom,aes256-ctr-md5-hmac;
				qcom,3des-cbc-md5-hmac;
				qcom,3des-cbc-sha160-hmac;
				qcom,aes128-cbc-sha256-hmac;
				qcom,aes192-cbc-sha256-hmac;
				qcom,aes256-cbc-sha256-hmac;
				qcom,aes128-ctr-sha256-hmac;
				qcom,aes192-ctr-sha256-hmac;
				qcom,aes256-ctr-sha256-hmac;
				qcom,3des-cbc-sha256-hmac;
				qcom,aes128-cbc-sha384-hmac;
				qcom,aes192-cbc-sha384-hmac;
				qcom,aes256-cbc-sha384-hmac;
				qcom,aes128-ctr-sha384-hmac;
				qcom,aes192-ctr-sha384-hmac;
				qcom,aes256-ctr-sha384-hmac;
				qcom,aes128-cbc-sha512-hmac;
				qcom,aes192-cbc-sha512-hmac;
				qcom,aes256-cbc-sha512-hmac;
				qcom,aes128-ctr-sha512-hmac;
				qcom,aes192-ctr-sha512-hmac;
				qcom,aes256-ctr-sha512-hmac;

				engine0 {
					reg_offset = <0x80000>;
					qcom,ifpp-enabled;
					qcom,ipue-enabled;
					qcom,ofpp-enabled;
					qcom,opue-enabled;
				};
			};
		};

		eip: eip197@39800000 {
			compatible = "qcom,eip";
			reg-names = "eip_pbase";
			reg = <0x39800000 0x7ffff>;
			reg_offset = <0x80000>;
			ranges;
			clocks = <&nsscc NSS_CC_CRYPTO_CLK>,
			<&nsscc NSS_CC_NSSNOC_CRYPTO_CLK>,
			<&nsscc NSS_CC_CRYPTO_PPE_CLK>;
			clock-names = "crypto_clk", "crypto_nocclk",
			"crypto_ppeclk";
			clock-frequency = /bits/ 64 <600000000 600000000 300000000>;
			qcom,inline-enabled;
			status = "ok";
			interrupts = <GIC_SPI 385 IRQ_TYPE_LEVEL_HIGH>,
				   <GIC_SPI 386 IRQ_TYPE_LEVEL_HIGH>,
				   <GIC_SPI 387 IRQ_TYPE_LEVEL_HIGH>,
				   <GIC_SPI 388 IRQ_TYPE_LEVEL_HIGH>;

			dma0 {
				tx_cpu = /bits/ 8 <0>;
				rx_cpu = /bits/ 8 <0>;
				ring-name = "lookaside";
				ring-id = /bits/ 8 <0>;
			};

			dma1 {
				tx_cpu = /bits/ 8 <1>;
				rx_cpu = /bits/ 8 <1>;
				ring-name = "lookaside";
				ring-id = /bits/ 8 <1>;
			};

			dma2 {
				tx_cpu = /bits/ 8 <2>;
				rx_cpu = /bits/ 8 <2>;
				ring-name = "lookaside";
				ring-id = /bits/ 8 <2>;
			};

			dma3 {
				tx_cpu = /bits/ 8 <3>;
				rx_cpu = /bits/ 8 <3>;
				ring-name = "lookaside";
				ring-id = /bits/ 8 <3>;
			};

			dma4 {
				tx_cpu = /bits/ 8 <0>;
				rx_cpu = /bits/ 8 <0>;
				ring-name = "hybrid";
				ring-id = /bits/ 8 <4>;
			};

			dma5 {
				tx_cpu = /bits/ 8 <1>;
				rx_cpu = /bits/ 8 <1>;
				ring-name = "hybrid";
				ring-id = /bits/ 8 <5>;
			};

			dma6 {
				tx_cpu = /bits/ 8 <2>;
				rx_cpu = /bits/ 8 <2>;
				ring-name = "hybrid";
				ring-id = /bits/ 8 <6>;
			};

			dma7 {
				tx_cpu = /bits/ 8 <3>;
				rx_cpu = /bits/ 8 <3>;
				ring-name = "hybrid";
				ring-id = /bits/ 8 <7>;
			};
		};

		eip_crypto: eip_crypto {
			compatible = "qcom,eip_crypto";
			status = "ok";
		};

		ssphy_0: ssphy@7D000 {
			compatible = "qcom,ipq9574-qmp-usb3-phy";
			reg = <0x7D000 0x1C4>;
			#clock-cells = <1>;
			#address-cells = <1>;
			#size-cells = <1>;
			ranges;

			clocks = <&gcc GCC_USB0_AUX_CLK>,
				 <&gcc GCC_USB0_PHY_CFG_AHB_CLK>;
			clock-names = "aux", "cfg_ahb";

			resets =  <&gcc GCC_USB0_PHY_BCR>,
				 <&gcc GCC_USB3PHY_0_PHY_BCR>;
			reset-names = "phy","common";
			status = "disabled";

			usb0_ssphy: lane@7D200 {
				reg = <0x0007D200 0x130>,	/* Tx */
				      <0x0007D400 0x200>,	/* Rx */
				      <0x0007D800 0x1F8>,	/* PCS  */
				      <0x0007D600 0x044>;	/* PCS misc */
				#phy-cells = <0>;
				clocks = <&gcc GCC_USB0_PIPE_CLK>;
				clock-names = "pipe0";
				clock-output-names = "gcc_usb0_pipe_clk_src";
			};
		};

		qusb_phy_0: qusb@7B000 {
		    compatible = "qcom,ipq9574-qusb2-phy";
		    reg = <0x07B000 0x180>;
		    #phy-cells = <0>;

		    clocks = <&gcc GCC_USB0_PHY_CFG_AHB_CLK>,
			     <&xo>;
		    clock-names = "cfg_ahb", "ref";

		    resets = <&gcc GCC_QUSB2_0_PHY_BCR>;
		    status = "disabled";
		};

		usb3: usb3@8A00000 {
			compatible = "qcom,ipq9574-dwc3", "qcom,dwc3";
			reg = <0x8AF8800 0x400>;
			#address-cells = <1>;
			#size-cells = <1>;
			ranges;

			clocks = <&gcc GCC_SNOC_USB_CLK>,
				<&gcc GCC_ANOC_USB_AXI_CLK>,
				<&gcc GCC_USB0_MASTER_CLK>,
				<&gcc GCC_USB0_SLEEP_CLK>,
				<&gcc GCC_USB0_MOCK_UTMI_CLK>;

			clock-names = "sys_noc_axi",
				"anoc_axi",
				"master",
				"sleep",
				"mock_utmi";

			assigned-clocks = <&gcc GCC_SNOC_USB_CLK>,
					  <&gcc GCC_ANOC_USB_AXI_CLK>,
					  <&gcc GCC_USB0_MASTER_CLK>,
					  <&gcc GCC_USB0_MOCK_UTMI_CLK>;
			assigned-clock-rates = <200000000>,
					       <200000000>,
					       <200000000>,
					       <24000000>;

			resets = <&gcc GCC_USB_BCR>;
			status = "disabled";

			dwc_0: dwc3@8A00000 {
				compatible = "snps,dwc3";
				reg = <0x8A00000 0xcd00>;
				interrupts = <GIC_SPI 140 IRQ_TYPE_LEVEL_HIGH>;
				phys = <&qusb_phy_0>, <&usb0_ssphy>;
				phy-names = "usb2-phy", "usb3-phy";
				tx-fifo-resize;
				snps,dis_ep_cache_eviction;
				snps,is-utmi-l1-suspend;
				snps,hird-threshold = /bits/ 8 <0x0>;
				snps,dis_u2_susphy_quirk;
				snps,dis_u3_susphy_quirk;
				snps,quirk-ref-clock-adjustment = <0xA87F0>;
				snps,quirk-ref-clock-period = <0x29>;
				dr_mode = "host";
			};
		};

		q6v5_wcss: remoteproc@cd00000 {
			compatible = "qcom,ipq9574-wcss-pil";
			reg = <0x0cd00000 0x4040>,
				<0x004ab000 0x20>,
				<0xCB50000 0x8>;
			reg-names = "qdsp6",
				    "rmb",
				    "wcmn";
			interrupts-extended = <&intc GIC_SPI 325 IRQ_TYPE_EDGE_RISING>,
					      <&wcss_smp2p_in 0 0>,
					      <&wcss_smp2p_in 1 0>,
					      <&wcss_smp2p_in 2 0>,
					      <&wcss_smp2p_in 3 0>;
			interrupt-names = "wdog",
					  "fatal",
					  "ready",
					  "handover",
					  "stop-ack";

			resets = <&gcc GCC_WCSSAON_RESET>,
				 <&gcc GCC_WCSS_BCR>,
				 <&gcc GCC_WCSS_Q6_BCR>;

			reset-names = "wcss_aon_reset",
				      "wcss_reset",
				      "wcss_q6_reset";

			clocks = <&gcc GCC_ANOC_WCSS_AXI_M_CLK>,
				 <&gcc GCC_WCSS_AHB_S_CLK>,
				 <&gcc GCC_WCSS_ECAHB_CLK>,
				 <&gcc GCC_WCSS_ACMT_CLK>,
				 <&gcc GCC_WCSS_AXI_M_CLK>,
				 <&gcc GCC_Q6_AXIM_CLK>,
				 <&gcc GCC_Q6_AXIM2_CLK>,
				 <&gcc GCC_Q6_AHB_CLK>,
				 <&gcc GCC_Q6_AHB_S_CLK>,
				 <&gcc GCC_Q6SS_BOOT_CLK>,
				 <&gcc GCC_WCSS_DBG_IFC_APB_BDG_CLK>,
				 <&gcc GCC_WCSS_DBG_IFC_ATB_BDG_CLK>,
				 <&gcc GCC_WCSS_DBG_IFC_DAPBUS_BDG_CLK>,
				 <&gcc GCC_WCSS_DBG_IFC_NTS_BDG_CLK>,
				 <&gcc GCC_WCSS_DBG_IFC_APB_CLK>,
				 <&gcc GCC_WCSS_DBG_IFC_ATB_CLK>,
				 <&gcc GCC_WCSS_DBG_IFC_DAPBUS_CLK>,
				 <&gcc GCC_WCSS_DBG_IFC_NTS_CLK>,
				 <&gcc GCC_Q6_TSCTR_1TO2_CLK>,
				 <&gcc GCC_Q6SS_ATBM_CLK>,
				 <&gcc GCC_Q6SS_PCLKDBG_CLK>,
				 <&gcc GCC_Q6SS_TRIG_CLK>,
				 <&gcc GCC_MEM_NOC_Q6_AXI_CLK>,
				 <&gcc GCC_WCSS_Q6_TBU_CLK>,
				 <&gcc GCC_SYS_NOC_WCSS_AHB_CLK>;

			clock-names = "anoc_wcss_axi_m",
				      "wcss_ahb_s",
				      "wcss_ecahb",
				      "wcss_acmt",
				      "wcss_axi_m",
				      "q6_axim",
				      "q6_axim2",
				      "q6_ahb",
				      "q6_ahb_s",
				      "q6ss_boot",
				      "dbg-apb-bdg",
				      "dbg-atb-bdg",
				      "dbg-dapbus-bdg",
				      "dbg-nts-bdg",
				      "dbg-apb",
				      "dbg-atb",
				      "dbg-dapbus",
				      "dbg-nts",
				      "q6_tsctr_1to2_clk",
				      "q6ss_atbm_clk",
				      "q6ss_pclkdbg_clk",
				      "q6ss_trig_clk",
				      "mem_noc_q6_axi",
				      "wcss_q6_tbu",
				      "sys_noc_wcss_ahb";

			assigned-clocks = <&gcc GCC_ANOC_WCSS_AXI_M_CLK>,
				 <&gcc GCC_WCSS_AHB_S_CLK>,
				 <&gcc GCC_WCSS_ECAHB_CLK>,
				 <&gcc GCC_WCSS_ACMT_CLK>,
				 <&gcc GCC_WCSS_AXI_M_CLK>,
				 <&gcc GCC_Q6_AXIM_CLK>,
				 <&gcc GCC_Q6_AXIM2_CLK>,
				 <&gcc GCC_Q6_AHB_CLK>,
				 <&gcc GCC_Q6_AHB_S_CLK>,
				 <&gcc GCC_Q6SS_BOOT_CLK>,
				 <&gcc GCC_MEM_NOC_Q6_AXI_CLK>,
				 <&gcc GCC_WCSS_Q6_TBU_CLK>,
				 <&gcc GCC_SYS_NOC_WCSS_AHB_CLK>;

			assigned-clock-rates = <266666667>,
						<133333333>,
						<133333333>,
						<133333333>,
						<266666667>,
						<533000000>,
						<342857143>,
						<133333333>,
						<133333333>,
						<342857143>,
						<533000000>,
						<533000000>,
						<133333333>;

			qcom,halt-regs = <&tcsr_q6_block 0xa000 0xd000 0x0>;

			qcom,smem-states = <&wcss_smp2p_out 0>,
					   <&wcss_smp2p_out 1>;
			qcom,smem-state-names = "shutdown",
						"stop";

			memory-region = <&q6_region>,
					<&m3_dump>,
					<&q6_etr_region>,
					<&q6_caldb_region>;

			glink-edge {
				interrupts = <GIC_SPI 321 IRQ_TYPE_EDGE_RISING>;
				qcom,remote-pid = <1>;
				mboxes = <&apcs_glb 8>;

				qrtr_requests {
					qcom,glink-channels = "IPCRTR";
				};
			};
		};

		pcie0_phy: phy@84000 {
			compatible = "qcom,ipq9574-qmp-gen3x1-pcie-phy";
			reg = <0x84000 0x1bc>; /* Serdes PLL */
			#address-cells = <1>;
			#size-cells = <1>;
			ranges;
			clocks = <&gcc GCC_PCIE0_AUX_CLK>,
				 <&gcc GCC_PCIE0_AHB_CLK>,
				 <&gcc GCC_ANOC_PCIE0_1LANE_M_CLK>,
				 <&gcc GCC_SNOC_PCIE0_1LANE_S_CLK>;
			clock-names = "aux", "cfg_ahb", "anoc_lane", "snoc_lane";

			assigned-clocks = <&gcc GCC_PCIE0_AUX_CLK>,
					  <&gcc GCC_PCIE0_AHB_CLK>,
					  <&gcc GCC_ANOC_PCIE0_1LANE_M_CLK>,
					  <&gcc GCC_SNOC_PCIE0_1LANE_S_CLK>;
			assigned-clock-rates = <20000000>,
					       <100000000>,
					       <240000000>,
					       <240000000>;

			resets = <&gcc GCC_PCIE0_PHY_BCR>,
				<&gcc GCC_PCIE0PHY_PHY_BCR>;
			reset-names = "phy", "common";

			status = "disabled";

			pcie0_lane: lane@84200 {
				reg = <0x84200 0x16c>, /* Serdes Tx */
				      <0x84400 0x200>, /* Serdes Rx */
				      <0x84800 0x4f4>; /* PCS: Lane0, COM, PCIE */
				#phy-cells = <0>;

				clocks = <&gcc GCC_PCIE0_PIPE_CLK>;
				clock-names = "pipe0";
				clock-output-names = "gcc_pcie0_pipe_clk_src";
				#clock-cells = <0>;
				gen3 = <1>;
			};
		};

		pcie1_phy: phy@fc000 {
			compatible = "qcom,ipq9574-qmp-gen3x1-pcie-phy";
			reg = <0xfc000 0x1bc>; /* Serdes PLL */
			#address-cells = <1>;
			#size-cells = <1>;
			ranges;

			clocks = <&gcc GCC_PCIE1_AUX_CLK>,
				 <&gcc GCC_PCIE1_AHB_CLK>,
				 <&gcc GCC_ANOC_PCIE1_1LANE_M_CLK>,
				 <&gcc GCC_SNOC_PCIE1_1LANE_S_CLK>;
			clock-names = "aux", "cfg_ahb", "anoc_lane", "snoc_lane";

			assigned-clocks = <&gcc GCC_PCIE1_AUX_CLK>,
					  <&gcc GCC_PCIE1_AHB_CLK>,
					  <&gcc GCC_ANOC_PCIE1_1LANE_M_CLK>,
					  <&gcc GCC_SNOC_PCIE1_1LANE_S_CLK>;
			assigned-clock-rates = <20000000>,
					       <100000000>,
					       <240000000>,
					       <240000000>;

			resets = <&gcc GCC_PCIE1_PHY_BCR>,
				<&gcc GCC_PCIE1PHY_PHY_BCR>;
			reset-names = "phy", "common";

			status = "disabled";

			pcie1_lane: lane@fc200 {
				reg = <0xfc200 0x16c>, /* Serdes Tx */
				      <0xfc400 0x200>, /* Serdes Rx */
				      <0xfc800 0x4f4>; /* PCS: Lane0, COM, PCIE */
				#phy-cells = <0>;

				clocks = <&gcc GCC_PCIE1_PIPE_CLK>;
				clock-names = "pipe0";
				clock-output-names = "gcc_pcie1_pipe_clk_src";
				#clock-cells = <0>;
				gen3 = <1>;
			};
		};

		pcie2_phy: phy@8c000 {
			compatible = "qcom,ipq9574-qmp-gen3x2-pcie-phy";
			reg = <0x8c000 0x1bc>; /* Serdes PLL */
			#address-cells = <1>;
			#size-cells = <1>;
			ranges;

			clocks = <&gcc GCC_PCIE2_AUX_CLK>,
				 <&gcc GCC_PCIE2_AHB_CLK>,
				 <&gcc GCC_ANOC_PCIE2_2LANE_M_CLK>,
				 <&gcc GCC_SNOC_PCIE2_2LANE_S_CLK>;
			clock-names = "aux", "cfg_ahb", "anoc_lane", "snoc_lane";

			assigned-clocks = <&gcc GCC_PCIE2_AUX_CLK>,
					  <&gcc GCC_PCIE2_AHB_CLK>,
					  <&gcc GCC_ANOC_PCIE2_2LANE_M_CLK>,
					  <&gcc GCC_SNOC_PCIE2_2LANE_S_CLK>;
			assigned-clock-rates = <20000000>,
					       <100000000>,
					       <342857143>,
					       <240000000>;

			resets = <&gcc GCC_PCIE2_PHY_BCR>,
				<&gcc GCC_PCIE2PHY_PHY_BCR>;
			reset-names = "phy", "common";

			status = "disabled";

			pcie2_lanes: lanes@8c200 {
				reg = <0x8c200 0x16c>, /* Serdes Tx0 */
				      <0x8c400 0x200>, /* Serdes Rx0 */
				      <0x8d000 0x4f4>, /* PCS: Lane0, COM, PCIE */
				      <0x8c600 0x16c>, /* Serdes Tx1 */
				      <0x8c800 0x200>; /* Serdes Rx1 */

				#phy-cells = <0>;

				clocks = <&gcc GCC_PCIE2_PIPE_CLK>;
				clock-names = "pipe0";
				clock-output-names = "gcc_pcie2_pipe_clk_src";
				#clock-cells = <0>;
				gen3 = <1>;
			};
		};

		pcie3_phy: phy@f4000 {
			compatible = "qcom,ipq9574-qmp-gen3x2-pcie-phy";
			reg = <0xf4000 0x1bc>; /* Serdes PLL */
			#address-cells = <1>;
			#size-cells = <1>;
			ranges;

			clocks = <&gcc GCC_PCIE3_AUX_CLK>,
				 <&gcc GCC_PCIE3_AHB_CLK>,
				 <&gcc GCC_ANOC_PCIE3_2LANE_M_CLK>,
				 <&gcc GCC_SNOC_PCIE3_2LANE_S_CLK>;
			clock-names = "aux", "cfg_ahb", "anoc_lane", "snoc_lane";

			assigned-clocks = <&gcc GCC_PCIE3_AUX_CLK>,
					  <&gcc GCC_PCIE3_AHB_CLK>,
					  <&gcc GCC_ANOC_PCIE3_2LANE_M_CLK>,
					  <&gcc GCC_SNOC_PCIE3_2LANE_S_CLK>;
			assigned-clock-rates = <20000000>,
					       <100000000>,
					       <342857143>,
					       <240000000>;

			resets = <&gcc GCC_PCIE3_PHY_BCR>,
				<&gcc GCC_PCIE3PHY_PHY_BCR>;
			reset-names = "phy", "common";

			status = "disabled";

			pcie3_lanes: lanes@f4200 {
				reg = <0xf4200 0x16c>, /* Serdes Tx0 */
				      <0xf4400 0x200>, /* Serdes Rx0 */
				      <0xf5000 0x4f4>, /* PCS: Lane0, COM, PCIE */
				      <0xf4600 0x16c>, /* Serdes Tx1 */
				      <0xf4800 0x200>; /* Serdes Rx1 */

				#phy-cells = <0>;

				clocks = <&gcc GCC_PCIE3_PIPE_CLK>;
				clock-names = "pipe0";
				clock-output-names = "gcc_pcie3_pipe_clk_src";
				#clock-cells = <0>;
				gen3 = <1>;
			};
		};

		pcie0_x1: pci@28000000 {
			compatible = "qti,pcie-ipq9574";
			reg =  <0x28000000 0xf1d>,
			       <0x28000F20 0xa8>,
			       <0x28001000 0x1000>,
			       <0x00080000 0x2000>,
			       <0x28100000 0x1000>,
			       <0x00618088 0x4>;
			reg-names = "dbi", "elbi", "atu", "parf", "config", "aggr_noc";
			device_type = "pci";
			linux,pci-domain = <1>;
			bus-range = <0x00 0xff>;
			num-lanes = <1>;
			#address-cells = <3>;
			#size-cells = <2>;
			slv-addr-space-sz = <0x8000000>;
			axi-halt-val = <0x1e>; /* increase halt window size to 1GB */
			enable-enum-retry;

			ranges = <0x81000000 0 0x28200000 0x28200000
				  0 0x00100000   /* downstream I/O */
				  0x82000000 0 0x28300000 0x28300000
				  0 0x07d00000>; /* non-prefetchable memory */

			#interrupt-cells = <1>;
			interrupt-map-mask = <0 0 0 0x7>;
			interrupt-map = <0 0 0 1 &intc 0 75
					 IRQ_TYPE_LEVEL_HIGH>, /* int_a */
					<0 0 0 2 &intc 0 78
					 IRQ_TYPE_LEVEL_HIGH>, /* int_b */
					<0 0 0 3 &intc 0 79
					 IRQ_TYPE_LEVEL_HIGH>, /* int_c */
					<0 0 0 4 &intc 0 83
					 IRQ_TYPE_LEVEL_HIGH>; /* int_d */

			interrupts = <GIC_SPI 51 IRQ_TYPE_LEVEL_HIGH>;
			interrupt-names = "global_irq";

			/* clocks and clock-names are used to enable the clock in CBCR */
			clocks = <&gcc GCC_PCIE0_AHB_CLK>,
				 <&gcc GCC_PCIE0_AUX_CLK>,
				 <&gcc GCC_PCIE0_AXI_M_CLK>,
				 <&gcc GCC_PCIE0_AXI_S_CLK>,
				 <&gcc GCC_PCIE0_AXI_S_BRIDGE_CLK>,
				 <&gcc GCC_PCIE0_RCHNG_CLK>;

			clock-names = "ahb",
				      "aux",
				      "axi_m",
				      "axi_s",
				      "axi_bridge",
				      "rchng";

			assigned-clocks = <&gcc GCC_PCIE0_AHB_CLK>,
					  <&gcc GCC_PCIE0_AUX_CLK>,
					  <&gcc GCC_PCIE0_AXI_S_BRIDGE_CLK>;
			assigned-clock-rates = <100000000>,
					       <20000000>,
					       <240000000>;

			resets = <&gcc GCC_PCIE0_PIPE_ARES>,
				 <&gcc GCC_PCIE0_CORE_STICKY_ARES>,
				 <&gcc GCC_PCIE0_AXI_S_STICKY_ARES>,
				 <&gcc GCC_PCIE0_AXI_S_ARES>,
				 <&gcc GCC_PCIE0_AXI_M_STICKY_ARES>,
				 <&gcc GCC_PCIE0_AXI_M_ARES>,
				 <&gcc GCC_PCIE0_AUX_ARES>,
				 <&gcc GCC_PCIE0_AHB_ARES>;

			reset-names = "pipe",
				      "sticky",
				      "axi_s_sticky",
				      "axi_s",
				      "axi_m_sticky",
				      "axi_m",
				      "aux",
				      "ahb";

			phys = <&pcie0_lane>;
			phy-names = "pciephy";

			msi-parent = <&v2m0>;
			nvmem-cells = <&pcie0_disable>;
			status = "disabled";
		};

		pcie1_x1: pci@10000000 {
			compatible = "qti,pcie-ipq9574";
			reg =  <0x10000000 0xf1d>,
			       <0x10000F20 0xa8>,
			       <0x10001000 0x1000>,
			       <0x000F8000 0x2000>,
			       <0x10100000 0x1000>,
			       <0x00618108 0x4>;
			reg-names = "dbi", "elbi", "atu", "parf", "config", "aggr_noc";
			device_type = "pci";
			linux,pci-domain = <2>;
			bus-range = <0x00 0xff>;
			num-lanes = <1>;
			#address-cells = <3>;
			#size-cells = <2>;
			slv-addr-space-sz = <0x8000000>;
			axi-halt-val = <0x1e>; /* increase halt window size to 1GB */
			enable-enum-retry;

			ranges = <0x81000000 0 0x10200000 0x10200000
				  0 0x00100000   /* downstream I/O */
				  0x82000000 0 0x10300000 0x10300000
				  0 0x07d00000>; /* non-prefetchable memory */

			#interrupt-cells = <1>;
			interrupt-map-mask = <0 0 0 0x7>;
			interrupt-map = <0 0 0 1 &intc 0 35
					 IRQ_TYPE_LEVEL_HIGH>, /* int_a */
					<0 0 0 2 &intc 0 49
					 IRQ_TYPE_LEVEL_HIGH>, /* int_b */
					<0 0 0 3 &intc 0 84
					 IRQ_TYPE_LEVEL_HIGH>, /* int_c */
					<0 0 0 4 &intc 0 85
					 IRQ_TYPE_LEVEL_HIGH>; /* int_d */

			interrupts = <GIC_SPI 25 IRQ_TYPE_LEVEL_HIGH>;
			interrupt-names = "global_irq";

			/* clocks and clock-names are used to enable the clock in CBCR */
			clocks = <&gcc GCC_PCIE1_AHB_CLK>,
				 <&gcc GCC_PCIE1_AUX_CLK>,
				 <&gcc GCC_PCIE1_AXI_M_CLK>,
				 <&gcc GCC_PCIE1_AXI_S_CLK>,
				 <&gcc GCC_PCIE1_AXI_S_BRIDGE_CLK>,
				 <&gcc GCC_PCIE1_RCHNG_CLK>;

			clock-names = "ahb",
				      "aux",
				      "axi_m",
				      "axi_s",
				      "axi_bridge",
				      "rchng";

			assigned-clocks = <&gcc GCC_PCIE1_AHB_CLK>,
					  <&gcc GCC_PCIE1_AUX_CLK>,
					  <&gcc GCC_PCIE1_AXI_S_BRIDGE_CLK>;
			assigned-clock-rates = <100000000>,
					       <20000000>,
					       <240000000>;

			resets = <&gcc GCC_PCIE1_PIPE_ARES>,
				 <&gcc GCC_PCIE1_CORE_STICKY_ARES>,
				 <&gcc GCC_PCIE1_AXI_S_STICKY_ARES>,
				 <&gcc GCC_PCIE1_AXI_S_ARES>,
				 <&gcc GCC_PCIE1_AXI_M_STICKY_ARES>,
				 <&gcc GCC_PCIE1_AXI_M_ARES>,
				 <&gcc GCC_PCIE1_AUX_ARES>,
				 <&gcc GCC_PCIE1_AHB_ARES>;

			reset-names = "pipe",
				      "sticky",
				      "axi_s_sticky",
				      "axi_s",
				      "axi_m_sticky",
				      "axi_m",
				      "aux",
				      "ahb";

			phys = <&pcie1_lane>;
			phy-names = "pciephy";

			msi-parent = <&v2m0>;
			nvmem-cells = <&pcie1_disable>;
			status = "disabled";
		};

		pcie2_x2: pci@20000000 {
			compatible = "qti,pcie-ipq9574";
			reg =  <0x20000000 0xf1d>,
			       <0x20000F20 0xa8>,
			       <0x20001000 0x1000>,
			       <0x88000 0x2000>,
			       <0x20100000 0x1000>;
			reg-names = "dbi", "elbi", "atu", "parf", "config";
			device_type = "pci";
			linux,pci-domain = <3>;
			bus-range = <0x00 0xff>;
			num-lanes =<2>;
			#address-cells = <3>;
			#size-cells = <2>;
			slv-addr-space-sz = <0x8000000>;
			axi-halt-val = <0x1e>; /* increase halt window size to 1GB */
			enable-enum-retry;

			ranges = <0x81000000 0 0x20200000 0x20200000
				  0 0x00100000   /* downstream I/O */
				  0x82000000 0 0x20300000 0x20300000
				  0 0x07d00000>; /* non-prefetchable memory */

			#interrupt-cells = <1>;
			interrupt-map-mask = <0 0 0 0x7>;
			interrupt-map = <0 0 0 1 &intc 0 164
					 IRQ_TYPE_LEVEL_HIGH>, /* int_a */
					<0 0 0 2 &intc 0 165
					 IRQ_TYPE_LEVEL_HIGH>, /* int_b */
					<0 0 0 3 &intc 0 186
					 IRQ_TYPE_LEVEL_HIGH>, /* int_c */
					<0 0 0 4 &intc 0 187
					 IRQ_TYPE_LEVEL_HIGH>; /* int_d */

			interrupts = <GIC_SPI 125 IRQ_TYPE_LEVEL_HIGH>;
			interrupt-names = "global_irq";

			/* clocks and clock-names are used to enable the clock in CBCR */
			clocks = <&gcc GCC_PCIE2_AHB_CLK>,
				 <&gcc GCC_PCIE2_AUX_CLK>,
				 <&gcc GCC_PCIE2_AXI_M_CLK>,
				 <&gcc GCC_PCIE2_AXI_S_CLK>,
				 <&gcc GCC_PCIE2_AXI_S_BRIDGE_CLK>,
				 <&gcc GCC_PCIE2_RCHNG_CLK>;

			clock-names = "ahb",
				      "aux",
				      "axi_m",
				      "axi_s",
				      "axi_bridge",
				      "rchng";

			assigned-clocks = <&gcc GCC_PCIE2_AHB_CLK>,
					  <&gcc GCC_PCIE2_AUX_CLK>,
					  <&gcc GCC_PCIE2_AXI_S_BRIDGE_CLK>;
			assigned-clock-rates = <100000000>,
					       <20000000>,
					       <240000000>;

			resets = <&gcc GCC_PCIE2_PIPE_ARES>,
				 <&gcc GCC_PCIE2_CORE_STICKY_ARES>,
				 <&gcc GCC_PCIE2_AXI_S_STICKY_ARES>,
				 <&gcc GCC_PCIE2_AXI_S_ARES>,
				 <&gcc GCC_PCIE2_AXI_M_STICKY_ARES>,
				 <&gcc GCC_PCIE2_AXI_M_ARES>,
				 <&gcc GCC_PCIE2_AUX_ARES>,
				 <&gcc GCC_PCIE2_AHB_ARES>;

			reset-names = "pipe",
				      "sticky",
				      "axi_s_sticky",
				      "axi_s",
				      "axi_m_sticky",
				      "axi_m",
				      "aux",
				      "ahb";

			phys = <&pcie2_lanes>;
			phy-names = "pciephy";

			msi-parent = <&v2m0>;
			nvmem-cells = <&pcie2_disable>;
			status = "disabled";
		};

		pcie3_x2: pci@18000000 {
			compatible = "qti,pcie-ipq9574";
			reg =  <0x18000000 0xf1d>,
			       <0x18000F20 0xa8>,
			       <0x18001000 0x1000>,
			       <0x000F0000 0x2000>,
			       <0x18100000 0x1000>;
			reg-names = "dbi", "elbi", "atu", "parf", "config";
			device_type = "pci";
			linux,pci-domain = <4>;
			bus-range = <0x00 0xff>;
			num-lanes = <2>;
			#address-cells = <3>;
			#size-cells = <2>;
			slv-addr-space-sz = <0x8000000>;
			axi-halt-val = <0x1e>; /* increase halt window size to 1GB */
			enable-enum-retry;

			ranges = <0x81000000 0 0x18200000 0x18200000
				  0 0x00100000   /* downstream I/O */
				  0x82000000 0 0x18300000 0x18300000
				  0 0x07d00000>; /* non-prefetchable memory */

			#interrupt-cells = <1>;
			interrupt-map-mask = <0 0 0 0x7>;
			interrupt-map = <0 0 0 1 &intc 0 189
					 IRQ_TYPE_LEVEL_HIGH>, /* int_a */
					<0 0 0 2 &intc 0 190
					 IRQ_TYPE_LEVEL_HIGH>, /* int_b */
					<0 0 0 3 &intc 0 191
					 IRQ_TYPE_LEVEL_HIGH>, /* int_c */
					<0 0 0 4 &intc 0 192
					 IRQ_TYPE_LEVEL_HIGH>; /* int_d */

			interrupts = <GIC_SPI 188 IRQ_TYPE_LEVEL_HIGH>;
			interrupt-names = "global_irq";

			/* clocks and clock-names are used to enable the clock in CBCR */
			clocks = <&gcc GCC_PCIE3_AHB_CLK>,
				 <&gcc GCC_PCIE3_AUX_CLK>,
				 <&gcc GCC_PCIE3_AXI_M_CLK>,
				 <&gcc GCC_PCIE3_AXI_S_CLK>,
				 <&gcc GCC_PCIE3_AXI_S_BRIDGE_CLK>,
				 <&gcc GCC_PCIE3_RCHNG_CLK>;

			clock-names = "ahb",
				      "aux",
				      "axi_m",
				      "axi_s",
				      "axi_bridge",
				      "rchng";

			assigned-clocks = <&gcc GCC_PCIE3_AHB_CLK>,
					  <&gcc GCC_PCIE3_AUX_CLK>,
					  <&gcc GCC_PCIE3_AXI_S_BRIDGE_CLK>;
			assigned-clock-rates = <100000000>,
					       <20000000>,
					       <240000000>;

			resets = <&gcc GCC_PCIE3_PIPE_ARES>,
				 <&gcc GCC_PCIE3_CORE_STICKY_ARES>,
				 <&gcc GCC_PCIE3_AXI_S_STICKY_ARES>,
				 <&gcc GCC_PCIE3_AXI_S_ARES>,
				 <&gcc GCC_PCIE3_AXI_M_STICKY_ARES>,
				 <&gcc GCC_PCIE3_AXI_M_ARES>,
				 <&gcc GCC_PCIE3_AUX_ARES>,
				 <&gcc GCC_PCIE3_AHB_ARES>;

			reset-names = "pipe",
				      "sticky",
				      "axi_s_sticky",
				      "axi_s",
				      "axi_m_sticky",
				      "axi_m",
				      "aux",
				      "ahb";

			phys = <&pcie3_lanes>;
			phy-names = "pciephy";

			msi-parent = <&v2m0>;
			nvmem-cells = <&pcie3_disable>;
			status = "disabled";
		};

		qti,rpm-log@29fc00 {
			compatible = "qti,rpm-log";
			reg = <0x29fc00 0x4000>;
			qti,rpm-addr-phys = <0x200000>;
			qti,offset-version = <4>;
			qti,offset-page-buffer-addr = <36>;
			qti,offset-log-len = <40>;
			qti,offset-log-len-mask = <44>;
			qti,offset-page-indices = <56>;
		};

		wifi0: wifi@c0000000 {
			compatible = "qcom,cnss-qca9574", "qcom,ipq9574-wifi";
			reg = <0xc000000 0x1000000>;
			qcom,hw-mode-id = <1>;
		#ifdef __IPQ_MEM_PROFILE_256_MB__
			qcom,tgt-mem-mode = <2>;
		#elif __IPQ_MEM_PROFILE_512_MB__
			qcom,tgt-mem-mode = <1>;
		#else
			qcom,tgt-mem-mode = <0>;
		#endif
			qcom,rproc = <&q6v5_wcss>;
			qcom,bdf-addr = <0x4B700000 0x4B700000 0x4B700000
					 0x0 0x0 0x0>;
			qcom,caldb-addr = <0x4D800000 0x4CA00000 0x0
					   0x0 0x0 0x0>;
			qcom,caldb-size = <0x500000>;
		#ifdef __IPQ_MEM_PROFILE_512_MB__
			m3-dump-addr = <0x4C800000>;
		#else
			m3-dump-addr = <0x4D600000>;
		#endif
			interrupts = <0 320 1>, /* o_wcss_apps_intr[0] =  */
				<0 319 1>,
				<0 318 1>,
				<0 316 1>,
				<0 315 1>,
				<0 314 1>,
				<0 311 1>,
				<0 310 1>,
				<0 411 1>,
				<0 410 1>,
				<0 40 1>,
				<0 39 1>,
				<0 302 1>,
				<0 301 1>,
				<0 37 1>,
				<0 36 1>,
				<0 296 1>,
				<0 295 1>,
				<0 294 1>,
				<0 293 1>,
				<0 292 1>,
				<0 291 1>,
				<0 290 1>,
				<0 289 1>,
				<0 288 1>, /* o_wcss_apps_intr[25] */

				<0 239 1>,
				<0 236 1>,
				<0 235 1>,
				<0 234 1>,
				<0 233 1>,
				<0 232 1>,
				<0 231 1>,
				<0 230 1>,
				<0 229 1>,
				<0 228 1>,
				<0 224 1>,
				<0 223 1>,

				<0 203 1>,

				<0 183 1>,
				<0 180 1>,
				<0 179 1>,
				<0 178 1>,
				<0 177 1>,
				<0 176 1>,

				<0 163 1>,
				<0 162 1>,
				<0 160 1>,
				<0 414 1>,
				<0 159 1>,
				<0 158 1>,
				<0 157 1>,
				<0 156 1>; /* o_wcss_apps_intr[51] */

			interrupt-names = "misc-pulse1",
				"misc-latch",
				"sw-exception",
				"ce0",
				"ce1",
				"ce2",
				"ce3",
				"ce4",
				"ce5",
				"ce6",
				"ce7",
				"ce8",
				"ce9",
				"ce10",
				"ce11",
				"host2wbm-desc-feed",
				"host2reo-re-injection",
				"host2reo-command",
				"host2rxdma-monitor-ring3",
				"host2rxdma-monitor-ring2",
				"host2rxdma-monitor-ring1",
				"reo2ost-exception",
				"wbm2host-rx-release",
				"reo2host-status",
				"reo2host-destination-ring4",
				"reo2host-destination-ring3",
				"reo2host-destination-ring2",
				"reo2host-destination-ring1",
				"rxdma2host-monitor-destination-mac3",
				"rxdma2host-monitor-destination-mac2",
				"rxdma2host-monitor-destination-mac1",
				"ppdu-end-interrupts-mac3",
				"ppdu-end-interrupts-mac2",
				"ppdu-end-interrupts-mac1",
				"rxdma2host-monitor-status-ring-mac3",
				"rxdma2host-monitor-status-ring-mac2",
				"rxdma2host-monitor-status-ring-mac1",
				"host2rxdma-host-buf-ring-mac3",
				"host2rxdma-host-buf-ring-mac2",
				"host2rxdma-host-buf-ring-mac1",
				"rxdma2host-destination-ring-mac3",
				"rxdma2host-destination-ring-mac2",
				"rxdma2host-destination-ring-mac1",
				"host2tcl-input-ring4",
				"host2tcl-input-ring3",
				"host2tcl-input-ring2",
				"host2tcl-input-ring1",
				"wbm2host-tx-completions-ring4",
				"wbm2host-tx-completions-ring3",
				"wbm2host-tx-completions-ring2",
				"wbm2host-tx-completions-ring1",
				"tcl2host-status-ring";
			status = "disabled";
			qcom,pta-num = <0>;
			qcom,coex-mode = <0x2>;
			qcom,bt-active-time = <0x12>;
			qcom,bt-priority-time = <0x0c>;
			qcom,coex-algo = <0x2>;
			qcom,pta-priority = <0x80800505>;
		};

		wifi1: wifi1@f00000 {
			compatible  = "qcom,cnss-qcn9000";
			qcom,wlan-ramdump-dynamic = <0x400000>;
			qrtr_node_id = <0x20>;
			qca,auto-restart;
			status = "disabled";
			interrupt-bmap = <0x100512>;
		};

		wifi2: wifi2@f00000 {
			compatible  = "qcom,cnss-qcn9000";
			qcom,wlan-ramdump-dynamic = <0x400000>;
			qrtr_node_id = <0x21>;
			qca,auto-restart;
			status = "disabled";
			interrupt-bmap = <0x100512>;
		};

		wifi3: wifi3@f00000 {
			compatible  = "qcom,cnss-qcn9000";
			qcom,wlan-ramdump-dynamic = <0x400000>;
			qrtr_node_id = <0x22>;
			qca,auto-restart;
			status = "disabled";
			interrupt-bmap = <0x100512>;
		};

		wifi4: wifi4@f00000 {
			compatible  = "qcom,cnss-qcn9224";
			qcom,wlan-ramdump-dynamic = <0x600000>;
			qrtr_node_id = <0x30>;
			qca,auto-restart;
			status = "disabled";
			interrupt-bmap = <0x100512>;
#ifdef __IPQ_MEM_PROFILE_512_MB__
			/* qcn9224 tgt-mem-mode=1 layout - 37MB
			 * +=========+==============+=========+
			 * |  Region | Start Offset |   Size  |
			 * +---------+--------------+---------+
			 * | HREMOTE |  0x4CF00000  |   20MB  |
			 * +---------+--------------+---------+
			 * | M3 Dump |  0x4E300000  |   1MB   |
			 * +---------+--------------+---------+
			 * |   ETR   |  0x4E400000  |   1MB   |
			 * +---------+--------------+---------+
			 * |  Caldb  |  0x4E500000  |   8MB   |
			 * +---------+--------------+---------+
			 * |Pageable |  0x4ED00000  |   7MB   |
			 * +==================================+
			 */
			base-addr = <0x4CF00000>;
			m3-dump-addr = <0x4E300000>;
			etr-addr = <0x4E400000>;
			caldb-addr = <0x4E500000>;
			pageable-addr = <0x4ED00000>;
			hremote-size = <0x1400000>;
			pageable-size = <0x700000>;
			tgt-mem-mode = <0x1>;
#else
			/* qcn9224 tgt-mem-mode=0 layout - 50MB
			 * +=========+==============+=========+
			 * |  Region | Start Offset |   Size  |
			 * +---------+--------------+---------+
			 * | HREMOTE |  0x4DD00000  |   28MB  |
			 * +---------+--------------+---------+
			 * | M3 Dump |  0x4F900000  |   1MB   |
			 * +---------+--------------+---------+
			 * |   ETR   |  0x4FA00000  |   1MB   |
			 * +---------+--------------+---------+
			 * |  Caldb  |  0x4FB00000  |   8MB   |
			 * +---------+--------------+---------+
			 * |Pageable |  0x50300000  |  12MB   |
			 * +==================================+
			 */
			base-addr = <0x4DD00000>;
			m3-dump-addr = <0x4F900000>;
			etr-addr = <0x4FA00000>;
			caldb-addr = <0x4FB00000>;
			pageable-addr = <0x50300000>;
			hremote-size = <0x1C00000>;
			pageable-size = <0xC00000>;
			tgt-mem-mode = <0x0>;
#endif
			caldb-size = <0x800000>;
			qca,extended-intc;
			interrupts-extended =
				<&qcn9224_in0 5 0>,
				<&qcn9224_in0 6 0>,
				<&qcn9224_in0 7 0>,
				<&qcn9224_in0 8 0>,
				<&qcn9224_in0 9 0>,
				<&qcn9224_in0 10 0>,
				<&qcn9224_in0 11 0>,
				<&qcn9224_in0 12 0>,
				<&qcn9224_in0 13 0>,
				<&qcn9224_in0 14 0>,
				<&qcn9224_in0 15 0>,
				<&qcn9224_in0 16 0>,
				<&qcn9224_in0 17 0>,
				<&qcn9224_in0 18 0>,
				<&qcn9224_in0 19 0>,
				<&qcn9224_in0 20 0>,
				<&qcn9224_in0 49 0>,
				<&qcn9224_in0 48 0>,
				<&qcn9224_in0 47 0>,
				<&qcn9224_in0 46 0>,
				<&qcn9224_in0 45 0>,
				<&qcn9224_in0 44 0>,
				<&qcn9224_in0 43 0>,
				<&qcn9224_in0 42 0>,
				<&qcn9224_in0 50 0>,
				<&qcn9224_in0 52 0>,
				<&qcn9224_in0 51 0>,
				<&qcn9224_in0 30 0>,
				<&qcn9224_in0 29 0>,
				<&qcn9224_in0 28 0>,
				<&qcn9224_in0 27 0>,
				<&qcn9224_in0 26 0>,
				<&qcn9224_in0 25 0>,
				<&qcn9224_in0 31 0>,
				<&qcn9224_in0 80 0>,
				<&qcn9224_in0 71 0>,
				<&qcn9224_in0 96 0>,
				<&qcn9224_in0 97 0>,
				<&qcn9224_in0 67 0>,
				<&qcn9224_in0 100 0>,
				<&qcn9224_in0 99 0>,
				<&qcn9224_in0 68 0>,
				<&qcn9224_in0 69 0>,
				<&qcn9224_in0 121 0>,
				<&qcn9224_in0 119 0>,
				<&qcn9224_in0 122 0>,
				<&qcn9224_in0 120 0>,
				<&qcn9224_in0 116 0>,
				<&qcn9224_in0 113 0>,
				<&qcn9224_in0 115 0>,
				<&qcn9224_in0 112 0>,
				<&qcn9224_in0 114 0>,
				<&qcn9224_in0 111 0>,
				<&qcn9224_in0 110 0>,
				<&qcn9224_in0 109 0>,
				<&qcn9224_in0 108 0>,
				<&qcn9224_in0 39 0>,
				<&qcn9224_in0 38 0>,
				<&qcn9224_in0 37 0>,
				<&qcn9224_in0 36 0>,
				<&qcn9224_in0 35 0>,
				<&qcn9224_in0 34 0>,
				<&qcn9224_in0 33 0>,
				<&qcn9224_in0 41 0>,
				<&qcn9224_in0 40 0>,
				<&qcn9224_in0 32 0>,
				<&qcn9224_in0 24 0>,
				<&qcn9224_in0 23 0>,
				<&qcn9224_in0 22 0>,
				<&qcn9224_in0 21 0>,
				<&qcn9224_in0 66 0>,
				<&qcn9224_in0 78 0>,
				<&qcn9224_in0 117 0>,
				<&qcn9224_in0 118 0>,
				<&qcn9224_in0 61 0>,
				<&qcn9224_in0 60 0>,
				<&qcn9224_in0 57 0>,
				<&qcn9224_in0 56 0>,
				<&qcn9224_in0 63 0>,
				<&qcn9224_in0 62 0>,
				<&qcn9224_in0 59 0>,
				<&qcn9224_in0 58 0>,
				<&qcn9224_in0 65 0>,
				<&qcn9224_in0 83 0>,
				<&qcn9224_in0 75 0>,
				<&qcn9224_in0 82 0>,
				<&qcn9224_in0 81 0>,
				<&qcn9224_in0 74 0>,
				<&qcn9224_in0 73 0>,
				<&qcn9224_in0 72 0>,
				<&qcn9224_in0 98 0>,
				<&qcn9224_in0 107 0>,
				<&qcn9224_in0 106 0>,
				<&qcn9224_in0 105 0>,
				<&qcn9224_in0 104 0>,
				<&qcn9224_in0 103 0>,
				<&qcn9224_in0 102 0>,
				<&qcn9224_in0 101 0>,
				<&qcn9224_in0 76 0>,
				<&qcn9224_in0 77 0>,
				<&qcn9224_in0 143 0>,
				<&qcn9224_in0 142 0>,
				<&qcn9224_in0 141 0>,
				<&intc GIC_SPI 75 IRQ_TYPE_LEVEL_HIGH>;

			interrupt-names = "ce0",
				"ce1",
				"ce2",
				"ce3",
				"ce4",
				"ce5",
				"ce6",
				"ce7",
				"ce8",
				"ce9",
				"ce10",
				"ce11",
				"ce12",
				"ce13",
				"ce14",
				"ce15",
				"reo2sw8_intr2",
				"reo2sw7_intr2",
				"reo2sw6_intr2",
				"reo2sw5_intr2",
				"reo2sw4_intr2",
				"reo2sw3_intr2",
				"reo2sw2_intr2",
				"reo2sw1_intr2",
				"reo2sw0_intr2",
				"reo2sw8_intr",
				"reo2sw7_intr",
				"reo2sw6_inrr",
				"reo2sw5_intr",
				"reo2sw4_intr",
				"reo2sw3_intr",
				"reo2sw2_intr",
				"reo2sw1_intr",
				"reo2sw0_intr",
				"reo2status_intr2",
				"reo_status",
				"reo2rxdma_out_2",
				"reo2rxdma_out_1",
				"reo_cmd",
				"sw2reo6",
				"sw2reo5",
				"sw2reo1",
				"sw2reo",
				"rxdma2reo_mlo_0_dst_ring1",
				"rxdma2reo_mlo_0_dst_ring0",
				"rxdma2reo_mlo_1_dst_ring1",
				"rxdma2reo_mlo_1_dst_ring0",
				"rxdma2reo_dst_ring1",
				"rxdma2reo_dst_ring0",
				"rxdma2sw_dst_ring1",
				"rxdma2sw_dst_ring0",
				"rxdma2release_dst_ring1",
				"rxdma2release_dst_ring0",
				"sw2rxdma_2_src_ring",
				"sw2rxdma_1_src_ring",
				"sw2rxdma_0",
				"wbm2sw6_release2",
				"wbm2sw5_release2",
				"wbm2sw4_release2",
				"wbm2sw3_release2",
				"wbm2sw2_release2",
				"wbm2sw1_release2",
				"wbm2sw0_release2",
				"wbm2sw6_release",
				"wbm2sw5_release",
				"wbm2sw4_release",
				"wbm2sw3_release",
				"wbm2sw2_release",
				"wbm2sw1_release",
				"wbm2sw0_release",
				"wbm2sw_link",
				"wbm_error_release",
				"sw2txmon_src_ring",
				"sw2rxmon_src_ring",
				"txmon2sw_p1_intr1",
				"txmon2sw_p1_intr0",
				"txmon2sw_p0_dest1",
				"txmon2sw_p0_dest0",
				"rxmon2sw_p1_intr1",
				"rxmon2sw_p1_intr0",
				"rxmon2sw_p0_dest1",
				"rxmon2sw_p0_dest0",
				"sw_release",
				"sw2tcl_credit2",
				"sw2tcl_credit",
				"sw2tcl4",
				"sw2tcl5",
				"sw2tcl3",
				"sw2tcl2",
				"sw2tcl1",
				"sw2wbm1",
				"misc_8",
				"misc_7",
				"misc_6",
				"misc_5",
				"misc_4",
				"misc_3",
				"misc_2",
				"misc_1",
				"misc_0",
				"mhi2",
				"mhi1",
				"mhi0",
				"inta";
		};


		wifi5: wifi5@f00000 {
			compatible  = "qcom,cnss-qcn9224";
			qcom,wlan-ramdump-dynamic = <0x600000>;
			qrtr_node_id = <0x31>;
			qca,auto-restart;
			status = "disabled";
			interrupt-bmap = <0x100512>;
#ifdef __IPQ_MEM_PROFILE_512_MB__
			/* qcn9224 tgt-mem-mode=1 layout - 37MB
			 * +=========+==============+=========+
			 * |  Region | Start Offset |   Size  |
			 * +---------+--------------+---------+
			 * | HREMOTE |  0x4F400000  |   20MB  |
			 * +---------+--------------+---------+
			 * | M3 Dump |  0x50800000  |   1MB   |
			 * +---------+--------------+---------+
			 * |   ETR   |  0x50900000  |   1MB   |
			 * +---------+--------------+---------+
			 * |  Caldb  |  0x50A00000  |   8MB   |
			 * +---------+--------------+---------+
			 * |Pageable |  0x51200000  |   7MB   |
			 * +==================================+
			 */
			base-addr = <0x4F400000>;
			m3-dump-addr = <0x50800000>;
			etr-addr = <0x50900000>;
			caldb-addr = <0x50A00000>;
			pageable-addr = <0x51200000>;
			hremote-size = <0x1400000>;
			pageable-size = <0x700000>;
			tgt-mem-mode = <0x1>;
#else
			/* qcn9224 tgt-mem-mode=0 layout - 50MB
			 * +=========+==============+=========+
			 * |  Region | Start Offset |   Size  |
			 * +---------+--------------+---------+
			 * | HREMOTE |  0x50F00000  |   28MB  |
			 * +---------+--------------+---------+
			 * | M3 Dump |  0x52B00000  |   1MB   |
			 * +---------+--------------+---------+
			 * |   ETR   |  0x52C00000  |   1MB   |
			 * +---------+--------------+---------+
			 * |  Caldb  |  0x52D00000  |   8MB   |
			 * +---------+--------------+---------+
			 * |Pageable |  0x53500000  |  12MB   |
			 * +==================================+
			 */
			base-addr = <0x50F00000>;
			m3-dump-addr = <0x52B00000>;
			etr-addr = <0x52C00000>;
			caldb-addr = <0x52D00000>;
			pageable-addr = <0x53500000>;
			hremote-size = <0x1C00000>;
			pageable-size = <0xC00000>;
			tgt-mem-mode = <0x0>;
#endif
			caldb-size = <0x800000>;
			qca,extended-intc;
			interrupts-extended =
				<&qcn9224_in1 5 0>,
				<&qcn9224_in1 6 0>,
				<&qcn9224_in1 7 0>,
				<&qcn9224_in1 8 0>,
				<&qcn9224_in1 9 0>,
				<&qcn9224_in1 10 0>,
				<&qcn9224_in1 11 0>,
				<&qcn9224_in1 12 0>,
				<&qcn9224_in1 13 0>,
				<&qcn9224_in1 14 0>,
				<&qcn9224_in1 15 0>,
				<&qcn9224_in1 16 0>,
				<&qcn9224_in1 17 0>,
				<&qcn9224_in1 18 0>,
				<&qcn9224_in1 19 0>,
				<&qcn9224_in1 20 0>,
				<&qcn9224_in1 49 0>,
				<&qcn9224_in1 48 0>,
				<&qcn9224_in1 47 0>,
				<&qcn9224_in1 46 0>,
				<&qcn9224_in1 45 0>,
				<&qcn9224_in1 44 0>,
				<&qcn9224_in1 43 0>,
				<&qcn9224_in1 42 0>,
				<&qcn9224_in1 50 0>,
				<&qcn9224_in1 52 0>,
				<&qcn9224_in1 51 0>,
				<&qcn9224_in1 30 0>,
				<&qcn9224_in1 29 0>,
				<&qcn9224_in1 28 0>,
				<&qcn9224_in1 27 0>,
				<&qcn9224_in1 26 0>,
				<&qcn9224_in1 25 0>,
				<&qcn9224_in1 31 0>,
				<&qcn9224_in1 80 0>,
				<&qcn9224_in1 71 0>,
				<&qcn9224_in1 96 0>,
				<&qcn9224_in1 97 0>,
				<&qcn9224_in1 67 0>,
				<&qcn9224_in1 100 0>,
				<&qcn9224_in1 99 0>,
				<&qcn9224_in1 68 0>,
				<&qcn9224_in1 69 0>,
				<&qcn9224_in1 121 0>,
				<&qcn9224_in1 119 0>,
				<&qcn9224_in1 122 0>,
				<&qcn9224_in1 120 0>,
				<&qcn9224_in1 116 0>,
				<&qcn9224_in1 113 0>,
				<&qcn9224_in1 115 0>,
				<&qcn9224_in1 112 0>,
				<&qcn9224_in1 114 0>,
				<&qcn9224_in1 111 0>,
				<&qcn9224_in1 110 0>,
				<&qcn9224_in1 109 0>,
				<&qcn9224_in1 108 0>,
				<&qcn9224_in1 39 0>,
				<&qcn9224_in1 38 0>,
				<&qcn9224_in1 37 0>,
				<&qcn9224_in1 36 0>,
				<&qcn9224_in1 35 0>,
				<&qcn9224_in1 34 0>,
				<&qcn9224_in1 33 0>,
				<&qcn9224_in1 41 0>,
				<&qcn9224_in1 40 0>,
				<&qcn9224_in1 32 0>,
				<&qcn9224_in1 24 0>,
				<&qcn9224_in1 23 0>,
				<&qcn9224_in1 22 0>,
				<&qcn9224_in1 21 0>,
				<&qcn9224_in1 66 0>,
				<&qcn9224_in1 78 0>,
				<&qcn9224_in1 117 0>,
				<&qcn9224_in1 118 0>,
				<&qcn9224_in1 61 0>,
				<&qcn9224_in1 60 0>,
				<&qcn9224_in1 57 0>,
				<&qcn9224_in1 56 0>,
				<&qcn9224_in1 63 0>,
				<&qcn9224_in1 62 0>,
				<&qcn9224_in1 59 0>,
				<&qcn9224_in1 58 0>,
				<&qcn9224_in1 65 0>,
				<&qcn9224_in1 83 0>,
				<&qcn9224_in1 75 0>,
				<&qcn9224_in1 82 0>,
				<&qcn9224_in1 81 0>,
				<&qcn9224_in1 74 0>,
				<&qcn9224_in1 73 0>,
				<&qcn9224_in1 72 0>,
				<&qcn9224_in1 98 0>,
				<&qcn9224_in1 107 0>,
				<&qcn9224_in1 106 0>,
				<&qcn9224_in1 105 0>,
				<&qcn9224_in1 104 0>,
				<&qcn9224_in1 103 0>,
				<&qcn9224_in1 102 0>,
				<&qcn9224_in1 101 0>,
				<&qcn9224_in1 76 0>,
				<&qcn9224_in1 77 0>,
				<&qcn9224_in1 143 0>,
				<&qcn9224_in1 142 0>,
				<&qcn9224_in1 141 0>,
				<&intc GIC_SPI 35 IRQ_TYPE_LEVEL_HIGH>;

			interrupt-names = "ce0",
				"ce1",
				"ce2",
				"ce3",
				"ce4",
				"ce5",
				"ce6",
				"ce7",
				"ce8",
				"ce9",
				"ce10",
				"ce11",
				"ce12",
				"ce13",
				"ce14",
				"ce15",
				"reo2sw8_intr2",
				"reo2sw7_intr2",
				"reo2sw6_intr2",
				"reo2sw5_intr2",
				"reo2sw4_intr2",
				"reo2sw3_intr2",
				"reo2sw2_intr2",
				"reo2sw1_intr2",
				"reo2sw0_intr2",
				"reo2sw8_intr",
				"reo2sw7_intr",
				"reo2sw6_inrr",
				"reo2sw5_intr",
				"reo2sw4_intr",
				"reo2sw3_intr",
				"reo2sw2_intr",
				"reo2sw1_intr",
				"reo2sw0_intr",
				"reo2status_intr2",
				"reo_status",
				"reo2rxdma_out_2",
				"reo2rxdma_out_1",
				"reo_cmd",
				"sw2reo6",
				"sw2reo5",
				"sw2reo1",
				"sw2reo",
				"rxdma2reo_mlo_0_dst_ring1",
				"rxdma2reo_mlo_0_dst_ring0",
				"rxdma2reo_mlo_1_dst_ring1",
				"rxdma2reo_mlo_1_dst_ring0",
				"rxdma2reo_dst_ring1",
				"rxdma2reo_dst_ring0",
				"rxdma2sw_dst_ring1",
				"rxdma2sw_dst_ring0",
				"rxdma2release_dst_ring1",
				"rxdma2release_dst_ring0",
				"sw2rxdma_2_src_ring",
				"sw2rxdma_1_src_ring",
				"sw2rxdma_0",
				"wbm2sw6_release2",
				"wbm2sw5_release2",
				"wbm2sw4_release2",
				"wbm2sw3_release2",
				"wbm2sw2_release2",
				"wbm2sw1_release2",
				"wbm2sw0_release2",
				"wbm2sw6_release",
				"wbm2sw5_release",
				"wbm2sw4_release",
				"wbm2sw3_release",
				"wbm2sw2_release",
				"wbm2sw1_release",
				"wbm2sw0_release",
				"wbm2sw_link",
				"wbm_error_release",
				"sw2txmon_src_ring",
				"sw2rxmon_src_ring",
				"txmon2sw_p1_intr1",
				"txmon2sw_p1_intr0",
				"txmon2sw_p0_dest1",
				"txmon2sw_p0_dest0",
				"rxmon2sw_p1_intr1",
				"rxmon2sw_p1_intr0",
				"rxmon2sw_p0_dest1",
				"rxmon2sw_p0_dest0",
				"sw_release",
				"sw2tcl_credit2",
				"sw2tcl_credit",
				"sw2tcl4",
				"sw2tcl5",
				"sw2tcl3",
				"sw2tcl2",
				"sw2tcl1",
				"sw2wbm1",
				"misc_8",
				"misc_7",
				"misc_6",
				"misc_5",
				"misc_4",
				"misc_3",
				"misc_2",
				"misc_1",
				"misc_0",
				"mhi2",
				"mhi1",
				"mhi0",
				"inta";
		};

		wifi6: wifi6@f00000 {
			compatible  = "qcom,cnss-qcn9224";
			qcom,wlan-ramdump-dynamic = <0x600000>;
			qrtr_node_id = <0x32>;
			qca,auto-restart;
			status = "disabled";
			interrupt-bmap = <0x100512>;
#ifdef __IPQ_MEM_PROFILE_512_MB__
			/* qcn9224 tgt-mem-mode=1 layout - 37MB
			 * +=========+==============+=========+
			 * |  Region | Start Offset |   Size  |
			 * +---------+--------------+---------+
			 * | HREMOTE |  0x51900000  |   20MB  |
			 * +---------+--------------+---------+
			 * | M3 Dump |  0x52D00000  |   1MB   |
			 * +---------+--------------+---------+
			 * |   ETR   |  0x52E00000  |   1MB   |
			 * +---------+--------------+---------+
			 * |  Caldb  |  0x52F00000  |   8MB   |
			 * +---------+--------------+---------+
			 * |Pageable |  0x53700000  |   7MB   |
			 * +==================================+
			 */
			base-addr = <0x51900000>;
			m3-dump-addr = <0x52D00000>;
			etr-addr = <0x52E00000>;
			caldb-addr = <0x52F00000>;
			pageable-addr = <0x53700000>;
			hremote-size = <0x1400000>;
			pageable-size = <0x700000>;
			tgt-mem-mode = <0x1>;
#else
			/* qcn9224 tgt-mem-mode=0 layout - 50MB
			 * +=========+==============+=========+
			 * |  Region | Start Offset |   Size  |
			 * +---------+--------------+---------+
			 * | HREMOTE |  0x54100000  |   28MB  |
			 * +---------+--------------+---------+
			 * | M3 Dump |  0x55D00000  |   1MB   |
			 * +---------+--------------+---------+
			 * |   ETR   |  0x55E00000  |   1MB   |
			 * +---------+--------------+---------+
			 * |  Caldb  |  0x55F00000  |   8MB   |
			 * +---------+--------------+---------+
			 * |Pageable |  0x56700000  |  12MB   |
			 * +==================================+
			 */
			base-addr = <0x54100000>;
			m3-dump-addr = <0x55D00000>;
			etr-addr = <0x55E00000>;
			caldb-addr = <0x55F00000>;
			pageable-addr = <0x56700000>;
			hremote-size = <0x1C00000>;
			pageable-size = <0xC00000>;
			tgt-mem-mode = <0x0>;
#endif
			caldb-size = <0x800000>;
			qca,extended-intc;
			interrupts-extended =
				<&qcn9224_in2 5 0>,
				<&qcn9224_in2 6 0>,
				<&qcn9224_in2 7 0>,
				<&qcn9224_in2 8 0>,
				<&qcn9224_in2 9 0>,
				<&qcn9224_in2 10 0>,
				<&qcn9224_in2 11 0>,
				<&qcn9224_in2 12 0>,
				<&qcn9224_in2 13 0>,
				<&qcn9224_in2 14 0>,
				<&qcn9224_in2 15 0>,
				<&qcn9224_in2 16 0>,
				<&qcn9224_in2 17 0>,
				<&qcn9224_in2 18 0>,
				<&qcn9224_in2 19 0>,
				<&qcn9224_in2 20 0>,
				<&qcn9224_in2 49 0>,
				<&qcn9224_in2 48 0>,
				<&qcn9224_in2 47 0>,
				<&qcn9224_in2 46 0>,
				<&qcn9224_in2 45 0>,
				<&qcn9224_in2 44 0>,
				<&qcn9224_in2 43 0>,
				<&qcn9224_in2 42 0>,
				<&qcn9224_in2 50 0>,
				<&qcn9224_in2 52 0>,
				<&qcn9224_in2 51 0>,
				<&qcn9224_in2 30 0>,
				<&qcn9224_in2 29 0>,
				<&qcn9224_in2 28 0>,
				<&qcn9224_in2 27 0>,
				<&qcn9224_in2 26 0>,
				<&qcn9224_in2 25 0>,
				<&qcn9224_in2 31 0>,
				<&qcn9224_in2 80 0>,
				<&qcn9224_in2 71 0>,
				<&qcn9224_in2 96 0>,
				<&qcn9224_in2 97 0>,
				<&qcn9224_in2 67 0>,
				<&qcn9224_in2 100 0>,
				<&qcn9224_in2 99 0>,
				<&qcn9224_in2 68 0>,
				<&qcn9224_in2 69 0>,
				<&qcn9224_in2 121 0>,
				<&qcn9224_in2 119 0>,
				<&qcn9224_in2 122 0>,
				<&qcn9224_in2 120 0>,
				<&qcn9224_in2 116 0>,
				<&qcn9224_in2 113 0>,
				<&qcn9224_in2 115 0>,
				<&qcn9224_in2 112 0>,
				<&qcn9224_in2 114 0>,
				<&qcn9224_in2 111 0>,
				<&qcn9224_in2 110 0>,
				<&qcn9224_in2 109 0>,
				<&qcn9224_in2 108 0>,
				<&qcn9224_in2 39 0>,
				<&qcn9224_in2 38 0>,
				<&qcn9224_in2 37 0>,
				<&qcn9224_in2 36 0>,
				<&qcn9224_in2 35 0>,
				<&qcn9224_in2 34 0>,
				<&qcn9224_in2 33 0>,
				<&qcn9224_in2 41 0>,
				<&qcn9224_in2 40 0>,
				<&qcn9224_in2 32 0>,
				<&qcn9224_in2 24 0>,
				<&qcn9224_in2 23 0>,
				<&qcn9224_in2 22 0>,
				<&qcn9224_in2 21 0>,
				<&qcn9224_in2 66 0>,
				<&qcn9224_in2 78 0>,
				<&qcn9224_in2 117 0>,
				<&qcn9224_in2 118 0>,
				<&qcn9224_in2 61 0>,
				<&qcn9224_in2 60 0>,
				<&qcn9224_in2 57 0>,
				<&qcn9224_in2 56 0>,
				<&qcn9224_in2 63 0>,
				<&qcn9224_in2 62 0>,
				<&qcn9224_in2 59 0>,
				<&qcn9224_in2 58 0>,
				<&qcn9224_in2 65 0>,
				<&qcn9224_in2 83 0>,
				<&qcn9224_in2 75 0>,
				<&qcn9224_in2 82 0>,
				<&qcn9224_in2 81 0>,
				<&qcn9224_in2 74 0>,
				<&qcn9224_in2 73 0>,
				<&qcn9224_in2 72 0>,
				<&qcn9224_in2 98 0>,
				<&qcn9224_in2 107 0>,
				<&qcn9224_in2 106 0>,
				<&qcn9224_in2 105 0>,
				<&qcn9224_in2 104 0>,
				<&qcn9224_in2 103 0>,
				<&qcn9224_in2 102 0>,
				<&qcn9224_in2 101 0>,
				<&qcn9224_in2 76 0>,
				<&qcn9224_in2 77 0>,
				<&qcn9224_in2 143 0>,
				<&qcn9224_in2 142 0>,
				<&qcn9224_in2 141 0>,
				<&intc GIC_SPI 164 IRQ_TYPE_LEVEL_HIGH>;

			interrupt-names = "ce0",
				"ce1",
				"ce2",
				"ce3",
				"ce4",
				"ce5",
				"ce6",
				"ce7",
				"ce8",
				"ce9",
				"ce10",
				"ce11",
				"ce12",
				"ce13",
				"ce14",
				"ce15",
				"reo2sw8_intr2",
				"reo2sw7_intr2",
				"reo2sw6_intr2",
				"reo2sw5_intr2",
				"reo2sw4_intr2",
				"reo2sw3_intr2",
				"reo2sw2_intr2",
				"reo2sw1_intr2",
				"reo2sw0_intr2",
				"reo2sw8_intr",
				"reo2sw7_intr",
				"reo2sw6_inrr",
				"reo2sw5_intr",
				"reo2sw4_intr",
				"reo2sw3_intr",
				"reo2sw2_intr",
				"reo2sw1_intr",
				"reo2sw0_intr",
				"reo2status_intr2",
				"reo_status",
				"reo2rxdma_out_2",
				"reo2rxdma_out_1",
				"reo_cmd",
				"sw2reo6",
				"sw2reo5",
				"sw2reo1",
				"sw2reo",
				"rxdma2reo_mlo_0_dst_ring1",
				"rxdma2reo_mlo_0_dst_ring0",
				"rxdma2reo_mlo_1_dst_ring1",
				"rxdma2reo_mlo_1_dst_ring0",
				"rxdma2reo_dst_ring1",
				"rxdma2reo_dst_ring0",
				"rxdma2sw_dst_ring1",
				"rxdma2sw_dst_ring0",
				"rxdma2release_dst_ring1",
				"rxdma2release_dst_ring0",
				"sw2rxdma_2_src_ring",
				"sw2rxdma_1_src_ring",
				"sw2rxdma_0",
				"wbm2sw6_release2",
				"wbm2sw5_release2",
				"wbm2sw4_release2",
				"wbm2sw3_release2",
				"wbm2sw2_release2",
				"wbm2sw1_release2",
				"wbm2sw0_release2",
				"wbm2sw6_release",
				"wbm2sw5_release",
				"wbm2sw4_release",
				"wbm2sw3_release",
				"wbm2sw2_release",
				"wbm2sw1_release",
				"wbm2sw0_release",
				"wbm2sw_link",
				"wbm_error_release",
				"sw2txmon_src_ring",
				"sw2rxmon_src_ring",
				"txmon2sw_p1_intr1",
				"txmon2sw_p1_intr0",
				"txmon2sw_p0_dest1",
				"txmon2sw_p0_dest0",
				"rxmon2sw_p1_intr1",
				"rxmon2sw_p1_intr0",
				"rxmon2sw_p0_dest1",
				"rxmon2sw_p0_dest0",
				"sw_release",
				"sw2tcl_credit2",
				"sw2tcl_credit",
				"sw2tcl4",
				"sw2tcl5",
				"sw2tcl3",
				"sw2tcl2",
				"sw2tcl1",
				"sw2wbm1",
				"misc_8",
				"misc_7",
				"misc_6",
				"misc_5",
				"misc_4",
				"misc_3",
				"misc_2",
				"misc_1",
				"misc_0",
				"mhi2",
				"mhi1",
				"mhi0",
				"inta";
		};

		wifi7: wifi7@f00000 {
			compatible  = "qcom,cnss-qcn9224";
			qcom,wlan-ramdump-dynamic = <0x600000>;
			qrtr_node_id = <0x33>;
			qca,auto-restart;
			status = "disabled";
			interrupt-bmap = <0x100512>;
#ifdef __IPQ_MEM_PROFILE_512_MB__
			/* qcn9224 tgt-mem-mode=1 layout - 37MB
			 * +=========+==============+=========+
			 * |  Region | Start Offset |   Size  |
			 * +---------+--------------+---------+
			 * | HREMOTE |  0x53E00000  |   20MB  |
			 * +---------+--------------+---------+
			 * | M3 Dump |  0x55200000  |   1MB   |
			 * +---------+--------------+---------+
			 * |   ETR   |  0x55300000  |   1MB   |
			 * +---------+--------------+---------+
			 * |  Caldb  |  0x55400000  |   8MB   |
			 * +---------+--------------+---------+
			 * |Pageable |  0x55C00000  |   7MB   |
			 * +==================================+
			 */
			base-addr = <0x53E00000>;
			m3-dump-addr = <0x55200000>;
			etr-addr = <0x55300000>;
			caldb-addr = <0x55400000>;
			pageable-addr = <0x55C00000>;
			hremote-size = <0x1400000>;
			pageable-size = <0x700000>;
			tgt-mem-mode = <0x1>;
#else
			/* qcn9224 tgt-mem-mode=0 layout - 50MB
			 * +=========+==============+=========+
			 * |  Region | Start Offset |   Size  |
			 * +---------+--------------+---------+
			 * | HREMOTE |  0x57300000  |   28MB  |
			 * +---------+--------------+---------+
			 * | M3 Dump |  0x58F00000  |   1MB   |
			 * +---------+--------------+---------+
			 * |   ETR   |  0x59000000  |   1MB   |
			 * +---------+--------------+---------+
			 * |  Caldb  |  0x59100000  |   8MB   |
			 * +---------+--------------+---------+
			 * |Pageable |  0x59900000  |  12MB   |
			 * +==================================+
			 */
			base-addr = <0x57300000>;
			m3-dump-addr = <0x58F00000>;
			etr-addr = <0x59000000>;
			caldb-addr = <0x59100000>;
			pageable-addr = <0x59900000>;
			hremote-size = <0x1C00000>;
			pageable-size = <0xC00000>;
			tgt-mem-mode = <0x0>;
#endif
			caldb-size = <0x800000>;
			qca,extended-intc;
			interrupts-extended =
				<&qcn9224_in3 5 0>,
				<&qcn9224_in3 6 0>,
				<&qcn9224_in3 7 0>,
				<&qcn9224_in3 8 0>,
				<&qcn9224_in3 9 0>,
				<&qcn9224_in3 10 0>,
				<&qcn9224_in3 11 0>,
				<&qcn9224_in3 12 0>,
				<&qcn9224_in3 13 0>,
				<&qcn9224_in3 14 0>,
				<&qcn9224_in3 15 0>,
				<&qcn9224_in3 16 0>,
				<&qcn9224_in3 17 0>,
				<&qcn9224_in3 18 0>,
				<&qcn9224_in3 19 0>,
				<&qcn9224_in3 20 0>,
				<&qcn9224_in3 49 0>,
				<&qcn9224_in3 48 0>,
				<&qcn9224_in3 47 0>,
				<&qcn9224_in3 46 0>,
				<&qcn9224_in3 45 0>,
				<&qcn9224_in3 44 0>,
				<&qcn9224_in3 43 0>,
				<&qcn9224_in3 42 0>,
				<&qcn9224_in3 50 0>,
				<&qcn9224_in3 52 0>,
				<&qcn9224_in3 51 0>,
				<&qcn9224_in3 30 0>,
				<&qcn9224_in3 29 0>,
				<&qcn9224_in3 28 0>,
				<&qcn9224_in3 27 0>,
				<&qcn9224_in3 26 0>,
				<&qcn9224_in3 25 0>,
				<&qcn9224_in3 31 0>,
				<&qcn9224_in3 80 0>,
				<&qcn9224_in3 71 0>,
				<&qcn9224_in3 96 0>,
				<&qcn9224_in3 97 0>,
				<&qcn9224_in3 67 0>,
				<&qcn9224_in3 100 0>,
				<&qcn9224_in3 99 0>,
				<&qcn9224_in3 68 0>,
				<&qcn9224_in3 69 0>,
				<&qcn9224_in3 121 0>,
				<&qcn9224_in3 119 0>,
				<&qcn9224_in3 122 0>,
				<&qcn9224_in3 120 0>,
				<&qcn9224_in3 116 0>,
				<&qcn9224_in3 113 0>,
				<&qcn9224_in3 115 0>,
				<&qcn9224_in3 112 0>,
				<&qcn9224_in3 114 0>,
				<&qcn9224_in3 111 0>,
				<&qcn9224_in3 110 0>,
				<&qcn9224_in3 109 0>,
				<&qcn9224_in3 108 0>,
				<&qcn9224_in3 39 0>,
				<&qcn9224_in3 38 0>,
				<&qcn9224_in3 37 0>,
				<&qcn9224_in3 36 0>,
				<&qcn9224_in3 35 0>,
				<&qcn9224_in3 34 0>,
				<&qcn9224_in3 33 0>,
				<&qcn9224_in3 41 0>,
				<&qcn9224_in3 40 0>,
				<&qcn9224_in3 32 0>,
				<&qcn9224_in3 24 0>,
				<&qcn9224_in3 23 0>,
				<&qcn9224_in3 22 0>,
				<&qcn9224_in3 21 0>,
				<&qcn9224_in3 66 0>,
				<&qcn9224_in3 78 0>,
				<&qcn9224_in3 117 0>,
				<&qcn9224_in3 118 0>,
				<&qcn9224_in3 61 0>,
				<&qcn9224_in3 60 0>,
				<&qcn9224_in3 57 0>,
				<&qcn9224_in3 56 0>,
				<&qcn9224_in3 63 0>,
				<&qcn9224_in3 62 0>,
				<&qcn9224_in3 59 0>,
				<&qcn9224_in3 58 0>,
				<&qcn9224_in3 65 0>,
				<&qcn9224_in3 83 0>,
				<&qcn9224_in3 75 0>,
				<&qcn9224_in3 82 0>,
				<&qcn9224_in3 81 0>,
				<&qcn9224_in3 74 0>,
				<&qcn9224_in3 73 0>,
				<&qcn9224_in3 72 0>,
				<&qcn9224_in3 98 0>,
				<&qcn9224_in3 107 0>,
				<&qcn9224_in3 106 0>,
				<&qcn9224_in3 105 0>,
				<&qcn9224_in3 104 0>,
				<&qcn9224_in3 103 0>,
				<&qcn9224_in3 102 0>,
				<&qcn9224_in3 101 0>,
				<&qcn9224_in3 76 0>,
				<&qcn9224_in3 77 0>,
				<&qcn9224_in3 143 0>,
				<&qcn9224_in3 142 0>,
				<&qcn9224_in3 141 0>,
				<&intc GIC_SPI 189 IRQ_TYPE_LEVEL_HIGH>;

			interrupt-names = "ce0",
				"ce1",
				"ce2",
				"ce3",
				"ce4",
				"ce5",
				"ce6",
				"ce7",
				"ce8",
				"ce9",
				"ce10",
				"ce11",
				"ce12",
				"ce13",
				"ce14",
				"ce15",
				"reo2sw8_intr2",
				"reo2sw7_intr2",
				"reo2sw6_intr2",
				"reo2sw5_intr2",
				"reo2sw4_intr2",
				"reo2sw3_intr2",
				"reo2sw2_intr2",
				"reo2sw1_intr2",
				"reo2sw0_intr2",
				"reo2sw8_intr",
				"reo2sw7_intr",
				"reo2sw6_inrr",
				"reo2sw5_intr",
				"reo2sw4_intr",
				"reo2sw3_intr",
				"reo2sw2_intr",
				"reo2sw1_intr",
				"reo2sw0_intr",
				"reo2status_intr2",
				"reo_status",
				"reo2rxdma_out_2",
				"reo2rxdma_out_1",
				"reo_cmd",
				"sw2reo6",
				"sw2reo5",
				"sw2reo1",
				"sw2reo",
				"rxdma2reo_mlo_0_dst_ring1",
				"rxdma2reo_mlo_0_dst_ring0",
				"rxdma2reo_mlo_1_dst_ring1",
				"rxdma2reo_mlo_1_dst_ring0",
				"rxdma2reo_dst_ring1",
				"rxdma2reo_dst_ring0",
				"rxdma2sw_dst_ring1",
				"rxdma2sw_dst_ring0",
				"rxdma2release_dst_ring1",
				"rxdma2release_dst_ring0",
				"sw2rxdma_2_src_ring",
				"sw2rxdma_1_src_ring",
				"sw2rxdma_0",
				"wbm2sw6_release2",
				"wbm2sw5_release2",
				"wbm2sw4_release2",
				"wbm2sw3_release2",
				"wbm2sw2_release2",
				"wbm2sw1_release2",
				"wbm2sw0_release2",
				"wbm2sw6_release",
				"wbm2sw5_release",
				"wbm2sw4_release",
				"wbm2sw3_release",
				"wbm2sw2_release",
				"wbm2sw1_release",
				"wbm2sw0_release",
				"wbm2sw_link",
				"wbm_error_release",
				"sw2txmon_src_ring",
				"sw2rxmon_src_ring",
				"txmon2sw_p1_intr1",
				"txmon2sw_p1_intr0",
				"txmon2sw_p0_dest1",
				"txmon2sw_p0_dest0",
				"rxmon2sw_p1_intr1",
				"rxmon2sw_p1_intr0",
				"rxmon2sw_p0_dest1",
				"rxmon2sw_p0_dest0",
				"sw_release",
				"sw2tcl_credit2",
				"sw2tcl_credit",
				"sw2tcl4",
				"sw2tcl5",
				"sw2tcl3",
				"sw2tcl2",
				"sw2tcl1",
				"sw2wbm1",
				"misc_8",
				"misc_7",
				"misc_6",
				"misc_5",
				"misc_4",
				"misc_3",
				"misc_2",
				"misc_1",
				"misc_0",
				"mhi2",
				"mhi1",
				"mhi0",
				"inta";
		};

		qfprom@a4000 {
			compatible = "qcom,qfprom";
			reg = <0xA4000 0x5a1>;
			#address-cells = <1>;
			#size-cells = <1>;

			cpu_speed_bin: cpu_speed_bin@15 {
				reg = <0x15 0x2>;
				bits = <7 2>;
			};

			pcie0_disable: pcie0_disable@1c {
				reg = <0x1c 0x1>;
				bits = <2 1>;
			};

			pcie1_disable: pcie1_disable@1c {
				reg = <0x1c 0x1>;
				bits = <3 1>;
			};

			pcie2_disable: pcie2_disable@1c {
				reg = <0x1c 0x1>;
				bits = <4 1>;
			};

			pcie3_disable: pcie3_disable@1c {
				reg = <0x1c 0x1>;
				bits = <5 1>;
			};
		};

		eud: qcom,msm-eud {
			compatible = "qcom,msm-eud";
			reg = <0x78000 0x1000>,
			      <0x79000 0x2000>,
			      <0x7a000 0x1000>;
			reg-names = "eud_base",
				    "eud_mode_mgr",
				    "eud_mode_mgr2";
			interrupts = <GIC_SPI 469 IRQ_TYPE_LEVEL_HIGH>;
			interrupt-names = "eud_irq";
			qcom,eud-clock-vote-req = <1>;
			clocks = <&gcc GCC_USB0_PHY_CFG_AHB_CLK>;
			clock-names = "eud_ahb2phy_clk";
			status = "disabled";
		};
	};

	license_manager:license-manager {
		compatible = "qti,license-manager-service";
		license-file = "";
	};

	psci {
		compatible = "arm,psci-1.0";
		method = "smc";
	};

	wcss: wcss-smp2p {
		compatible = "qcom,smp2p";
		qcom,smem = <435>, <428>;

		interrupt-parent = <&intc>;
		interrupts = <GIC_SPI 322 IRQ_TYPE_EDGE_RISING>;

		mboxes = <&apcs_glb 9>;

		qcom,local-pid = <0>;
		qcom,remote-pid = <1>;

		wcss_smp2p_out: master-kernel {
			qcom,entry-name = "master-kernel";
			qcom,smp2p-feature-ssr-ack;
			#qcom,smem-state-cells = <1>;
		};

		wcss_smp2p_in: slave-kernel {
			qcom,entry-name = "slave-kernel";
			interrupt-controller;
			#interrupt-cells = <2>;
		};
	};

	qti,sps {
		compatible = "qti,msm-sps-4k";
		qti,pipe-attr-ee;
	};

	rpm-glink {
		compatible = "qcom,glink-rpm";
		interrupts = <GIC_SPI 168 IRQ_TYPE_EDGE_RISING>;
		qcom,rpm-msg-ram = <&rpm_msg_ram>;
		mboxes = <&apcs_glb 0>;

		rpm_requests: glink-channel {
			compatible = "qcom,rpm-ipq9574";
			qcom,glink-channels = "rpm_requests";

			regulators {
				compatible = "qcom,rpm-ipq9574-mp5496-regulators";

				ipq9574_s1: s1 {
					regulator-min-microvolt = <587500>;
					regulator-max-microvolt = <1075000>;
					regulator-always-on;
				};
				ipq9574_s2: s2 {
					regulator-min-microvolt = <700000>;
					regulator-max-microvolt = <1000000>;
					regulator-always-on;
				};
				ipq9574_s4: s4 {
					regulator-min-microvolt = <1>;
					regulator-max-microvolt = <9>;
					regulator-always-on;
				};
			};
		};
	};

	qti,scm_restart_reason {
		compatible = "qti_ipq9574,scm_restart_reason";
	};

	qti,gadget_diag@0 {
		     compatible = "qti,gadget-diag";
		     status = "disabled";
	};
};

#include "ipq9574-coresight.dtsi"
#include "ipq9574-thermal.dtsi"
#include "ipq9574-cpr-regulator.dtsi"
#include "ipq9574-noc.dtsi"
